VERSION "created by canmatrix"

NS_ :

BS_:

BU_: RadarFrontRight RadarFrontLeft DASy

BO_ 3221225472 VECTOR__INDEPENDENT_SIG_MSG: 0 Vector__XXX
 SG_ New_Signal_1313 : 0|8@1+ (1,0) [0|0] "" Vector__XXX
 SG_ ADAS_ModulationOffRequest : 0|2@1+ (1,0) [0|3] "" Vector__XXX

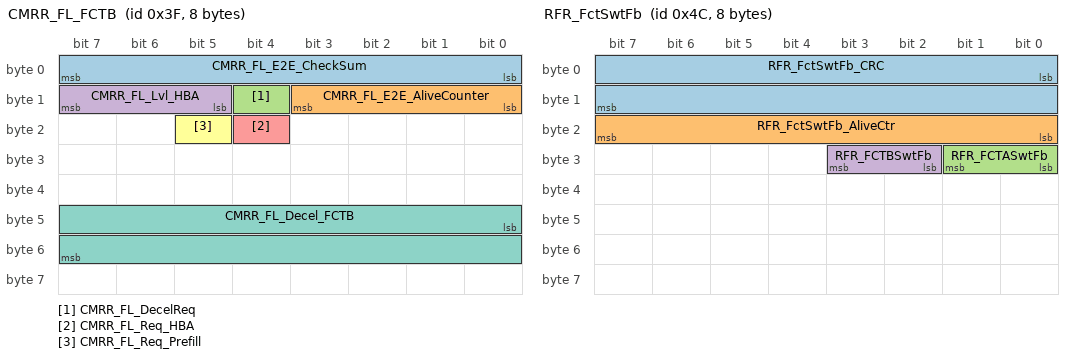
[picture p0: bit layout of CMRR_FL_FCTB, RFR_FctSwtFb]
BO_ 63 CMRR_FL_FCTB: 8 RadarFrontLeft
 SG_ CMRR_FL_E2E_CheckSum : 0|8@1+ (1,0) [0|255] ""  RadarFrontRight
 SG_ CMRR_FL_E2E_AliveCounter : 8|4@1+ (1,0) [0|14] ""  RadarFrontRight
 SG_ CMRR_FL_DecelReq : 12|1@1+ (1,0) [0|1] ""  RadarFrontRight
 SG_ CMRR_FL_Lvl_HBA : 13|3@1+ (1,0) [0|7] ""  RadarFrontRight
 SG_ CMRR_FL_Req_HBA : 20|1@1+ (1,0) [0|1] ""  RadarFrontRight
 SG_ CMRR_FL_Req_Prefill : 21|1@1+ (1,0) [0|1] ""  RadarFrontRight
 SG_ CMRR_FL_Decel_FCTB : 40|16@1+ (0.0004882,-16) [-16|15.994187] "m/s^2"  RadarFrontRight

BO_ 76 RFR_FctSwtFb: 8 RadarFrontRight
 SG_ RFR_FctSwtFb_CRC : 0|16@1+ (1,0) [0|65535] ""  DASy
 SG_ RFR_FctSwtFb_AliveCtr : 16|8@1+ (1,0) [0|255] ""  DASy
 SG_ RFR_FCTASwtFb : 24|2@1+ (1,0) [0|3] ""  DASy
 SG_ RFR_FCTBSwtFb : 26|2@1+ (1,0) [0|3] ""  DASy

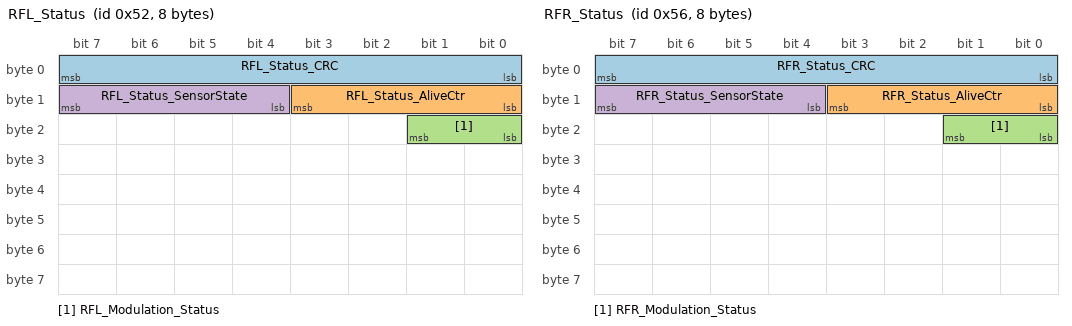
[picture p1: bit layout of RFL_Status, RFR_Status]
BO_ 82 RFL_Status: 8 RadarFrontLeft
 SG_ RFL_Status_CRC : 0|8@1+ (1,0) [0|255] ""  DASy
 SG_ RFL_Status_AliveCtr : 8|4@1+ (1,0) [0|14] ""  DASy
 SG_ RFL_Modulation_Status : 16|2@1+ (1,0) [0|3] ""  DASy
 SG_ RFL_Status_SensorState : 12|4@1+ (1,0) [0|15] ""  DASy

BO_ 86 RFR_Status: 8 RadarFrontRight
 SG_ RFR_Status_CRC : 0|8@1+ (1,0) [0|255] ""  DASy
 SG_ RFR_Status_AliveCtr : 8|4@1+ (1,0) [0|14] ""  DASy
 SG_ RFR_Modulation_Status : 16|2@1+ (1,0) [0|3] ""  DASy
 SG_ RFR_Status_SensorState : 12|4@1+ (1,0) [0|15] ""  DASy

BO_ 517 RFL_ObjHdr: 48 RadarFrontLeft
 SG_ RFL_ObjHdr_CRC : 0|16@1+ (1,0) [0|65535] ""  DASy
 SG_ RFL_ObjHdr_MountPosY : 128|8@1+ (0.01,-1.28) [-1.28|1.27] "m"  DASy
 SG_ RFL_ObjHdr_MountPosX : 136|9@1+ (0.02,-5.12) [-5.12|5.1] "m"  DASy
 SG_ RFL_ObjHdr_MountPosZ : 145|5@1+ (0.05,0) [0|1.55] "m"  DASy
 SG_ RFL_ObjHdr_ObjectDownSel : 151|1@1+ (1,0) [0|1] ""  DASy
 SG_ RFL_ObjHdr_YawMountAngle : 152|16@1+ (0.00017,-5.57056) [-3.2|3.2] "rad"  DASy
 SG_ RFL_ObjHdr_YawAngleLower : 168|15@1+ (0.00017,-2.78528) [-1.6|1.6] "rad"  DASy
 SG_ RFL_ObjHdr_AliveCtr : 16|8@1+ (1,0) [0|255] ""  DASy
 SG_ RFL_ObjHdr_AziOutOfSpec : 183|1@1+ (1,0) [0|1] ""  DASy
 SG_ RFL_ObjHdr_YawAngleUpper : 184|15@1+ (0.00017,-2.78528) [-1.6|1.6] "rad"  DASy
 SG_ RFL_ObjHdr_ElevOutOfSpec : 199|1@1+ (1,0) [0|1] ""  DASy
 SG_ RFL_ObjHdr_PitchMountAngle : 200|12@1+ (0.00017,-0.34816) [-0.2|0.2] "rad"  DASy
 SG_ RFL_ObjHdr_PitchAngleLower : 212|12@1+ (0.00017,-0.34816) [-0.2|0.2] "rad"  DASy
 SG_ RFL_ObjHdr_PitchAngleUpper : 224|12@1+ (0.00017,-0.34816) [-0.2|0.2] "rad"  DASy
 SG_ RFL_ObjHdr_RollMountAngle : 236|12@1+ (0.00017,-0.34816) [-0.2|0.2] "rad"  DASy
 SG_ RFL_ObjHdr_DetectionRange : 248|9@1+ (1,0) [0|511] "m"  DASy
 SG_ RFL_ObjHdr_ProtBlockCtr : 24|4@1+ (1,0) [0|15] ""  DASy
 SG_ RFL_ObjHdr_SensorState : 28|4@1+ (1,0) [0|15] ""  DASy
 SG_ RFL_ObjHdr_ProtocolVersion : 32|16@1+ (1,0) [0|65535] ""  DASy
 SG_ RFL_ObjHdr_ProtObjectCount : 48|6@1+ (1,0) [0|40] ""  DASy
 SG_ RFL_ObjHdr_TimeStampStatus : 88|8@1+ (1,0) [0|255] ""  DASy
 SG_ RFL_ObjHdr_TimeStamp : 96|26@1+ (1,0) [0|67108863] "ms"  DASy

BO_ 528 RFL_Obj00A: 64 RadarFrontLeft
 SG_ RFL_Obj00A_CRC : 0|16@1+ (1,0) [0|65535] ""  DASy
 SG_ RFL_Obj00A_Ay : 103|9@1+ (0.0625,-16) [-16|15.9375] "m/s^2"  DASy
 SG_ RFL_Obj00A_HeadingYawAngle : 112|9@1+ (0.0175,-4.48) [-3.15|3.15] "rad"  DASy
 SG_ RFL_Obj00A_Length : 121|7@1+ (0.125,0) [0|15.875] "m"  DASy
 SG_ RFL_Obj00A_Width : 128|7@1+ (0.125,0) [0|15.875] "m"  DASy
 SG_ RFL_Obj00A_Height : 135|7@1+ (0.125,0) [0|15.875] "m"  DASy
 SG_ RFL_Obj00A_DxVnce : 142|12@1+ (0.01,0) [0|30] "m^2"  DASy
 SG_ RFL_Obj00A_DyVnce : 154|12@1+ (0.01,0) [0|30] "m^2"  DASy
 SG_ RFL_Obj00A_DzVnce : 166|10@1+ (0.01,0) [0|10] "m^2"  DASy
 SG_ RFL_Obj00A_AliveCtr : 16|8@1+ (1,0) [0|255] ""  DASy
 SG_ RFL_Obj00A_VxVnce : 176|12@1+ (0.01,0) [0|30] "m^2/s^2"  DASy
 SG_ RFL_Obj00A_VyVnce : 188|12@1+ (0.01,0) [0|30] "m^2/s^2"  DASy
 SG_ RFL_Obj00A_AxVnce : 200|12@1+ (0.01,0) [0|30] "m^2/s^4"  DASy
 SG_ RFL_Obj00A_AyVnce : 212|12@1+ (0.01,0) [0|30] "m^2/s^4"  DASy
 SG_ RFL_Obj00A_RefPosIndex : 224|4@1+ (1,0) [0|15] ""  DASy
 SG_ RFL_Obj00A_DxDyCoVnce : 228|12@1+ (0.01,0) [0|30] "m^2"  DASy
 SG_ RFL_Obj00A_DxVxCoVnce : 240|12@1+ (0.01,0) [0|30] "m^2/s"  DASy
 SG_ RFL_Obj00A_ProtBlockCtr : 24|4@1+ (1,0) [0|15] ""  DASy
 SG_ RFL_Obj00A_DyVxCoVnce : 252|12@1+ (0.01,0) [0|30] "m^2/s"  DASy
 SG_ RFL_Obj00A_DxVyCoVnce : 264|12@1+ (0.01,0) [0|30] "m^2/s"  DASy
 SG_ RFL_Obj00A_DyVyCoVnce : 276|12@1+ (0.01,0) [0|30] "m^2/s"  DASy
 SG_ RFL_Obj00A_VxVyCoVnce : 288|12@1+ (0.01,0) [0|30] "m^2/s^2"  DASy
 SG_ RFL_Obj00A_DxAxCoVnce : 300|12@1+ (0.01,0) [0|30] "m^2/s^2"  DASy
 SG_ RFL_Obj00A_DyAxCoVnce : 312|12@1+ (0.01,0) [0|30] "m^2/s^2"  DASy
 SG_ RFL_Obj00A_VxAxCoVnce : 324|12@1+ (0.01,0) [0|30] "m^2/s^3"  DASy
 SG_ RFL_Obj00A_ID : 32|7@1+ (1,0) [0|127] ""  DASy
 SG_ RFL_Obj00A_VyAxCoVnce : 336|12@1+ (0.01,0) [0|30] "m^2/s^3"  DASy
 SG_ RFL_Obj00A_DxAyCoVnce : 348|12@1+ (0.01,0) [0|30] "m^2/s^2"  DASy
 SG_ RFL_Obj00A_DyAyCoVnce : 360|12@1+ (0.01,0) [0|30] "m^2/s^2"  DASy
 SG_ RFL_Obj00A_VxAyCoVnce : 372|12@1+ (0.01,0) [0|30] "m^2/s^3"  DASy
 SG_ RFL_Obj00A_VyAyCoVnce : 384|12@1+ (0.01,0) [0|30] "m^2/s^3"  DASy
 SG_ RFL_Obj00A_AxAyCoVnce : 396|12@1+ (0.01,0) [0|30] "m^2/s^4"  DASy
 SG_ RFL_Obj00A_Measured : 39|1@1+ (1,0) [0|1] ""  DASy
 SG_ RFL_Obj00A_HeadingYawAngleVnce : 408|12@1+ (0.0003,0) [0|1] "rad^2"  DASy
 SG_ RFL_Obj00A_Dx : 40|13@1+ (0.0625,-256) [-256|255.9375] "m"  DASy
 SG_ RFL_Obj00A_LengthVnce : 420|12@1+ (0.01,0) [0|30] "m^2"  DASy
 SG_ RFL_Obj00A_WidthVnce : 432|12@1+ (0.01,0) [0|30] "m^2"  DASy
 SG_ RFL_Obj00A_HeightVnce : 444|12@1+ (0.01,0) [0|30] "m^2"  DASy
 SG_ RFL_Obj00A_ProbExist : 456|6@1+ (2,0) [0|100] "%"  DASy
 SG_ RFL_Obj00A_ProbObstacle : 462|6@1+ (2,0) [0|100] "%"  DASy
 SG_ RFL_Obj00A_ProbNonObstacle : 468|6@1+ (2,0) [0|100] "%"  DASy
 SG_ RFL_Obj00A_ProbMobileObst : 474|6@1+ (2,0) [0|100] "%"  DASy
 SG_ RFL_Obj00A_Dz : 53|6@1+ (0.25,-5) [-5|10.75] "m"  DASy
 SG_ RFL_Obj00A_Dy : 59|11@1+ (0.125,-128) [-128|127.875] "m"  DASy
 SG_ RFL_Obj00A_Valid : 70|1@1+ (1,0) [0|1] ""  DASy
 SG_ RFL_Obj00A_Vx : 71|12@1+ (0.0625,-128) [-128|127.9375] "m/s"  DASy
 SG_ RFL_Obj00A_Vy : 83|10@1+ (0.125,-64) [-64|63.875] "m/s"  DASy
 SG_ RFL_Obj00A_Ax : 93|10@1+ (0.03125,-16) [-16|15.96875] "m/s^2"  DASy

BO_ 529 RFL_Obj00B: 12 RadarFrontLeft
 SG_ RFL_Obj00B_CRC : 0|16@1+ (1,0) [0|65535] ""  DASy
 SG_ RFL_Obj00B_AliveCtr : 16|8@1+ (1,0) [0|255] ""  DASy
 SG_ RFL_Obj00B_ProtBlockCtr : 24|4@1+ (1,0) [0|15] ""  DASy
 SG_ RFL_Obj00B_ProbMob4PlusWhl : 28|6@1+ (2,0) [0|100] "%"  DASy
 SG_ RFL_Obj00B_ProbMob2Whl : 34|6@1+ (2,0) [0|100] "%"  DASy
 SG_ RFL_Obj00B_ProbMobPed : 40|6@1+ (2,0) [0|100] "%"  DASy
 SG_ RFL_Obj00B_Prob4PlusWhlCAR : 46|6@1+ (2,0) [0|100] "%"  DASy
 SG_ RFL_Obj00B_Prob4PlusWhlbHGV : 52|6@1+ (2,0) [0|100] "%"  DASy
 SG_ RFL_Obj00B_ProbGNDReflex : 58|6@1+ (2,0) [0|100] "%"  DASy
 SG_ RFL_Obj00B_ProbStatBarrier : 64|6@1+ (2,0) [0|100] "%"  DASy
 SG_ RFL_Obj00B_ProbStatObst : 70|6@1+ (2,0) [0|100] "%"  DASy
 SG_ RFL_Obj00B_MovingProbability : 76|6@1+ (2,0) [0|100] "%"  DASy
 SG_ RFL_Obj00B_MovingObserved : 82|6@1+ (2,0) [0|100] "%"  DASy
 SG_ RFL_Obj00B_BehaviorType : 88|3@1+ (1,0) [0|7] ""  DASy

BO_ 530 RFL_Obj01A: 64 RadarFrontLeft
 SG_ RFL_Obj01A_CRC : 0|16@1+ (1,0) [0|65535] ""  DASy
 SG_ RFL_Obj01A_Ay : 103|9@1+ (0.0625,-16) [-16|15.9375] "m/s^2"  DASy
 SG_ RFL_Obj01A_HeadingYawAngle : 112|9@1+ (0.0175,-4.48) [-3.15|3.15] "rad"  DASy
 SG_ RFL_Obj01A_Length : 121|7@1+ (0.125,0) [0|15.875] "m"  DASy
 SG_ RFL_Obj01A_Width : 128|7@1+ (0.125,0) [0|15.875] "m"  DASy
 SG_ RFL_Obj01A_Height : 135|7@1+ (0.125,0) [0|15.875] "m"  DASy
 SG_ RFL_Obj01A_DxVnce : 142|12@1+ (0.01,0) [0|30] "m^2"  DASy
 SG_ RFL_Obj01A_DyVnce : 154|12@1+ (0.01,0) [0|30] "m^2"  DASy
 SG_ RFL_Obj01A_DzVnce : 166|10@1+ (0.01,0) [0|10] "m^2"  DASy
 SG_ RFL_Obj01A_AliveCtr : 16|8@1+ (1,0) [0|255] ""  DASy
 SG_ RFL_Obj01A_VxVnce : 176|12@1+ (0.01,0) [0|30] "m^2/s^2"  DASy
 SG_ RFL_Obj01A_VyVnce : 188|12@1+ (0.01,0) [0|30] "m^2/s^2"  DASy
 SG_ RFL_Obj01A_AxVnce : 200|12@1+ (0.01,0) [0|30] "m^2/s^4"  DASy
 SG_ RFL_Obj01A_AyVnce : 212|12@1+ (0.01,0) [0|30] "m^2/s^4"  DASy
 SG_ RFL_Obj01A_RefPosIndex : 224|4@1+ (1,0) [0|15] ""  DASy
 SG_ RFL_Obj01A_DxDyCoVnce : 228|12@1+ (0.01,0) [0|30] "m^2"  DASy
 SG_ RFL_Obj01A_DxVxCoVnce : 240|12@1+ (0.01,0) [0|30] "m^2/s"  DASy
 SG_ RFL_Obj01A_ProtBlockCtr : 24|4@1+ (1,0) [0|15] ""  DASy
 SG_ RFL_Obj01A_DyVxCoVnce : 252|12@1+ (0.01,0) [0|30] "m^2/s"  DASy
 SG_ RFL_Obj01A_DxVyCoVnce : 264|12@1+ (0.01,0) [0|30] "m^2/s"  DASy
 SG_ RFL_Obj01A_DyVyCoVnce : 276|12@1+ (0.01,0) [0|30] "m^2/s"  DASy
 SG_ RFL_Obj01A_VxVyCoVnce : 288|12@1+ (0.01,0) [0|30] "m^2/s^2"  DASy
 SG_ RFL_Obj01A_DxAxCoVnce : 300|12@1+ (0.01,0) [0|30] "m^2/s^2"  DASy
 SG_ RFL_Obj01A_DyAxCoVnce : 312|12@1+ (0.01,0) [0|30] "m^2/s^2"  DASy
 SG_ RFL_Obj01A_VxAxCoVnce : 324|12@1+ (0.01,0) [0|30] "m^2/s^3"  DASy
 SG_ RFL_Obj01A_ID : 32|7@1+ (1,0) [0|127] ""  DASy
 SG_ RFL_Obj01A_VyAxCoVnce : 336|12@1+ (0.01,0) [0|30] "m^2/s^3"  DASy
 SG_ RFL_Obj01A_DxAyCoVnce : 348|12@1+ (0.01,0) [0|30] "m^2/s^2"  DASy
 SG_ RFL_Obj01A_DyAyCoVnce : 360|12@1+ (0.01,0) [0|30] "m^2/s^2"  DASy
 SG_ RFL_Obj01A_VxAyCoVnce : 372|12@1+ (0.01,0) [0|30] "m^2/s^3"  DASy
 SG_ RFL_Obj01A_VyAyCoVnce : 384|12@1+ (0.01,0) [0|30] "m^2/s^3"  DASy
 SG_ RFL_Obj01A_AxAyCoVnce : 396|12@1+ (0.01,0) [0|30] "m^2/s^4"  DASy
 SG_ RFL_Obj01A_Measured : 39|1@1+ (1,0) [0|1] ""  DASy
 SG_ RFL_Obj01A_HeadingYawAngleVnce : 408|12@1+ (0.0003,0) [0|1] "rad^2"  DASy
 SG_ RFL_Obj01A_Dx : 40|13@1+ (0.0625,-256) [-256|255.9375] "m"  DASy
 SG_ RFL_Obj01A_LengthVnce : 420|12@1+ (0.01,0) [0|30] "m^2"  DASy
 SG_ RFL_Obj01A_WidthVnce : 432|12@1+ (0.01,0) [0|30] "m^2"  DASy
 SG_ RFL_Obj01A_HeightVnce : 444|12@1+ (0.01,0) [0|30] "m^2"  DASy
 SG_ RFL_Obj01A_ProbExist : 456|6@1+ (2,0) [0|100] "%"  DASy
 SG_ RFL_Obj01A_ProbObstacle : 462|6@1+ (2,0) [0|100] "%"  DASy
 SG_ RFL_Obj01A_ProbNonObstacle : 468|6@1+ (2,0) [0|100] "%"  DASy
 SG_ RFL_Obj01A_ProbMobileObst : 474|6@1+ (2,0) [0|100] "%"  DASy
 SG_ RFL_Obj01A_Dz : 53|6@1+ (0.25,-5) [-5|10.75] "m"  DASy
 SG_ RFL_Obj01A_Dy : 59|11@1+ (0.125,-128) [-128|127.875] "m"  DASy
 SG_ RFL_Obj01A_Valid : 70|1@1+ (1,0) [0|1] ""  DASy
 SG_ RFL_Obj01A_Vx : 71|12@1+ (0.0625,-128) [-128|127.9375] "m/s"  DASy
 SG_ RFL_Obj01A_Vy : 83|10@1+ (0.125,-64) [-64|63.875] "m/s"  DASy
 SG_ RFL_Obj01A_Ax : 93|10@1+ (0.03125,-16) [-16|15.96875] "m/s^2"  DASy

BO_ 531 RFL_Obj01B: 12 RadarFrontLeft
 SG_ RFL_Obj01B_CRC : 0|16@1+ (1,0) [0|65535] ""  DASy
 SG_ RFL_Obj01B_AliveCtr : 16|8@1+ (1,0) [0|255] ""  DASy
 SG_ RFL_Obj01B_ProtBlockCtr : 24|4@1+ (1,0) [0|15] ""  DASy
 SG_ RFL_Obj01B_ProbMob4PlusWhl : 28|6@1+ (2,0) [0|100] "%"  DASy
 SG_ RFL_Obj01B_ProbMob2Whl : 34|6@1+ (2,0) [0|100] "%"  DASy
 SG_ RFL_Obj01B_ProbMobPed : 40|6@1+ (2,0) [0|100] "%"  DASy
 SG_ RFL_Obj01B_Prob4PlusWhlCAR : 46|6@1+ (2,0) [0|100] "%"  DASy
 SG_ RFL_Obj01B_Prob4PlusWhlbHGV : 52|6@1+ (2,0) [0|100] "%"  DASy
 SG_ RFL_Obj01B_ProbGNDReflex : 58|6@1+ (2,0) [0|100] "%"  DASy
 SG_ RFL_Obj01B_ProbStatBarrier : 64|6@1+ (2,0) [0|100] "%"  DASy
 SG_ RFL_Obj01B_ProbStatObst : 70|6@1+ (2,0) [0|100] "%"  DASy
 SG_ RFL_Obj01B_MovingProbability : 76|6@1+ (2,0) [0|100] "%"  DASy
 SG_ RFL_Obj01B_MovingObserved : 82|6@1+ (2,0) [0|100] "%"  DASy
 SG_ RFL_Obj01B_BehaviorType : 88|3@1+ (1,0) [0|7] ""  DASy

BO_ 532 RFL_Obj02A: 64 RadarFrontLeft
 SG_ RFL_Obj02A_CRC : 0|16@1+ (1,0) [0|65535] ""  DASy
 SG_ RFL_Obj02A_Ay : 103|9@1+ (0.0625,-16) [-16|15.9375] "m/s^2"  DASy
 SG_ RFL_Obj02A_HeadingYawAngle : 112|9@1+ (0.0175,-4.48) [-3.15|3.15] "rad"  DASy
 SG_ RFL_Obj02A_Length : 121|7@1+ (0.125,0) [0|15.875] "m"  DASy
 SG_ RFL_Obj02A_Width : 128|7@1+ (0.125,0) [0|15.875] "m"  DASy
 SG_ RFL_Obj02A_Height : 135|7@1+ (0.125,0) [0|15.875] "m"  DASy
 SG_ RFL_Obj02A_DxVnce : 142|12@1+ (0.01,0) [0|30] "m^2"  DASy
 SG_ RFL_Obj02A_DyVnce : 154|12@1+ (0.01,0) [0|30] "m^2"  DASy
 SG_ RFL_Obj02A_DzVnce : 166|10@1+ (0.01,0) [0|10] "m^2"  DASy
 SG_ RFL_Obj02A_AliveCtr : 16|8@1+ (1,0) [0|255] ""  DASy
 SG_ RFL_Obj02A_VxVnce : 176|12@1+ (0.01,0) [0|30] "m^2/s^2"  DASy
 SG_ RFL_Obj02A_VyVnce : 188|12@1+ (0.01,0) [0|30] "m^2/s^2"  DASy
 SG_ RFL_Obj02A_AxVnce : 200|12@1+ (0.01,0) [0|30] "m^2/s^4"  DASy
 SG_ RFL_Obj02A_AyVnce : 212|12@1+ (0.01,0) [0|30] "m^2/s^4"  DASy
 SG_ RFL_Obj02A_RefPosIndex : 224|4@1+ (1,0) [0|15] ""  DASy
 SG_ RFL_Obj02A_DxDyCoVnce : 228|12@1+ (0.01,0) [0|30] "m^2"  DASy
 SG_ RFL_Obj02A_DxVxCoVnce : 240|12@1+ (0.01,0) [0|30] "m^2/s"  DASy
 SG_ RFL_Obj02A_ProtBlockCtr : 24|4@1+ (1,0) [0|15] ""  DASy
 SG_ RFL_Obj02A_DyVxCoVnce : 252|12@1+ (0.01,0) [0|30] "m^2/s"  DASy
 SG_ RFL_Obj02A_DxVyCoVnce : 264|12@1+ (0.01,0) [0|30] "m^2/s"  DASy
 SG_ RFL_Obj02A_DyVyCoVnce : 276|12@1+ (0.01,0) [0|30] "m^2/s"  DASy
 SG_ RFL_Obj02A_VxVyCoVnce : 288|12@1+ (0.01,0) [0|30] "m^2/s^2"  DASy
 SG_ RFL_Obj02A_DxAxCoVnce : 300|12@1+ (0.01,0) [0|30] "m^2/s^2"  DASy
 SG_ RFL_Obj02A_DyAxCoVnce : 312|12@1+ (0.01,0) [0|30] "m^2/s^2"  DASy
 SG_ RFL_Obj02A_VxAxCoVnce : 324|12@1+ (0.01,0) [0|30] "m^2/s^3"  DASy
 SG_ RFL_Obj02A_ID : 32|7@1+ (1,0) [0|127] ""  DASy
 SG_ RFL_Obj02A_VyAxCoVnce : 336|12@1+ (0.01,0) [0|30] "m^2/s^3"  DASy
 SG_ RFL_Obj02A_DxAyCoVnce : 348|12@1+ (0.01,0) [0|30] "m^2/s^2"  DASy
 SG_ RFL_Obj02A_DyAyCoVnce : 360|12@1+ (0.01,0) [0|30] "m^2/s^2"  DASy
 SG_ RFL_Obj02A_VxAyCoVnce : 372|12@1+ (0.01,0) [0|30] "m^2/s^3"  DASy
 SG_ RFL_Obj02A_VyAyCoVnce : 384|12@1+ (0.01,0) [0|30] "m^2/s^3"  DASy
 SG_ RFL_Obj02A_AxAyCoVnce : 396|12@1+ (0.01,0) [0|30] "m^2/s^4"  DASy
 SG_ RFL_Obj02A_Measured : 39|1@1+ (1,0) [0|1] ""  DASy
 SG_ RFL_Obj02A_HeadingYawAngleVnce : 408|12@1+ (0.0003,0) [0|1] "rad^2"  DASy
 SG_ RFL_Obj02A_Dx : 40|13@1+ (0.0625,-256) [-256|255.9375] "m"  DASy
 SG_ RFL_Obj02A_LengthVnce : 420|12@1+ (0.01,0) [0|30] "m^2"  DASy
 SG_ RFL_Obj02A_WidthVnce : 432|12@1+ (0.01,0) [0|30] "m^2"  DASy
 SG_ RFL_Obj02A_HeightVnce : 444|12@1+ (0.01,0) [0|30] "m^2"  DASy
 SG_ RFL_Obj02A_ProbExist : 456|6@1+ (2,0) [0|100] "%"  DASy
 SG_ RFL_Obj02A_ProbObstacle : 462|6@1+ (2,0) [0|100] "%"  DASy
 SG_ RFL_Obj02A_ProbNonObstacle : 468|6@1+ (2,0) [0|100] "%"  DASy
 SG_ RFL_Obj02A_ProbMobileObst : 474|6@1+ (2,0) [0|100] "%"  DASy
 SG_ RFL_Obj02A_Dz : 53|6@1+ (0.25,-5) [-5|10.75] "m"  DASy
 SG_ RFL_Obj02A_Dy : 59|11@1+ (0.125,-128) [-128|127.875] "m"  DASy
 SG_ RFL_Obj02A_Valid : 70|1@1+ (1,0) [0|1] ""  DASy
 SG_ RFL_Obj02A_Vx : 71|12@1+ (0.0625,-128) [-128|127.9375] "m/s"  DASy
 SG_ RFL_Obj02A_Vy : 83|10@1+ (0.125,-64) [-64|63.875] "m/s"  DASy
 SG_ RFL_Obj02A_Ax : 93|10@1+ (0.03125,-16) [-16|15.96875] "m/s^2"  DASy

BO_ 533 RFL_Obj02B: 12 RadarFrontLeft
 SG_ RFL_Obj02B_CRC : 0|16@1+ (1,0) [0|65535] ""  DASy
 SG_ RFL_Obj02B_AliveCtr : 16|8@1+ (1,0) [0|255] ""  DASy
 SG_ RFL_Obj02B_ProtBlockCtr : 24|4@1+ (1,0) [0|15] ""  DASy
 SG_ RFL_Obj02B_ProbMob4PlusWhl : 28|6@1+ (2,0) [0|100] "%"  DASy
 SG_ RFL_Obj02B_ProbMob2Whl : 34|6@1+ (2,0) [0|100] "%"  DASy
 SG_ RFL_Obj02B_ProbMobPed : 40|6@1+ (2,0) [0|100] "%"  DASy
 SG_ RFL_Obj02B_Prob4PlusWhlCAR : 46|6@1+ (2,0) [0|100] "%"  DASy
 SG_ RFL_Obj02B_Prob4PlusWhlbHGV : 52|6@1+ (2,0) [0|100] "%"  DASy
 SG_ RFL_Obj02B_ProbGNDReflex : 58|6@1+ (2,0) [0|100] "%"  DASy
 SG_ RFL_Obj02B_ProbStatBarrier : 64|6@1+ (2,0) [0|100] "%"  DASy
 SG_ RFL_Obj02B_ProbStatObst : 70|6@1+ (2,0) [0|100] "%"  DASy
 SG_ RFL_Obj02B_MovingProbability : 76|6@1+ (2,0) [0|100] "%"  DASy
 SG_ RFL_Obj02B_MovingObserved : 82|6@1+ (2,0) [0|100] "%"  DASy
 SG_ RFL_Obj02B_BehaviorType : 88|3@1+ (1,0) [0|7] ""  DASy

BO_ 534 RFL_Obj03A: 64 RadarFrontLeft
 SG_ RFL_Obj03A_CRC : 0|16@1+ (1,0) [0|65535] ""  DASy
 SG_ RFL_Obj03A_Ay : 103|9@1+ (0.0625,-16) [-16|15.9375] "m/s^2"  DASy
 SG_ RFL_Obj03A_HeadingYawAngle : 112|9@1+ (0.0175,-4.48) [-3.15|3.15] "rad"  DASy
 SG_ RFL_Obj03A_Length : 121|7@1+ (0.125,0) [0|15.875] "m"  DASy
 SG_ RFL_Obj03A_Width : 128|7@1+ (0.125,0) [0|15.875] "m"  DASy
 SG_ RFL_Obj03A_Height : 135|7@1+ (0.125,0) [0|15.875] "m"  DASy
 SG_ RFL_Obj03A_DxVnce : 142|12@1+ (0.01,0) [0|30] "m^2"  DASy
 SG_ RFL_Obj03A_DyVnce : 154|12@1+ (0.01,0) [0|30] "m^2"  DASy
 SG_ RFL_Obj03A_DzVnce : 166|10@1+ (0.01,0) [0|10] "m^2"  DASy
 SG_ RFL_Obj03A_AliveCtr : 16|8@1+ (1,0) [0|255] ""  DASy
 SG_ RFL_Obj03A_VxVnce : 176|12@1+ (0.01,0) [0|30] "m^2/s^2"  DASy
 SG_ RFL_Obj03A_VyVnce : 188|12@1+ (0.01,0) [0|30] "m^2/s^2"  DASy
 SG_ RFL_Obj03A_AxVnce : 200|12@1+ (0.01,0) [0|30] "m^2/s^4"  DASy
 SG_ RFL_Obj03A_AyVnce : 212|12@1+ (0.01,0) [0|30] "m^2/s^4"  DASy
 SG_ RFL_Obj03A_RefPosIndex : 224|4@1+ (1,0) [0|15] ""  DASy
 SG_ RFL_Obj03A_DxDyCoVnce : 228|12@1+ (0.01,0) [0|30] "m^2"  DASy
 SG_ RFL_Obj03A_DxVxCoVnce : 240|12@1+ (0.01,0) [0|30] "m^2/s"  DASy
 SG_ RFL_Obj03A_ProtBlockCtr : 24|4@1+ (1,0) [0|15] ""  DASy
 SG_ RFL_Obj03A_DyVxCoVnce : 252|12@1+ (0.01,0) [0|30] "m^2/s"  DASy
 SG_ RFL_Obj03A_DxVyCoVnce : 264|12@1+ (0.01,0) [0|30] "m^2/s"  DASy
 SG_ RFL_Obj03A_DyVyCoVnce : 276|12@1+ (0.01,0) [0|30] "m^2/s"  DASy
 SG_ RFL_Obj03A_VxVyCoVnce : 288|12@1+ (0.01,0) [0|30] "m^2/s^2"  DASy
 SG_ RFL_Obj03A_DxAxCoVnce : 300|12@1+ (0.01,0) [0|30] "m^2/s^2"  DASy
 SG_ RFL_Obj03A_DyAxCoVnce : 312|12@1+ (0.01,0) [0|30] "m^2/s^2"  DASy
 SG_ RFL_Obj03A_VxAxCoVnce : 324|12@1+ (0.01,0) [0|30] "m^2/s^3"  DASy
 SG_ RFL_Obj03A_ID : 32|7@1+ (1,0) [0|127] ""  DASy
 SG_ RFL_Obj03A_VyAxCoVnce : 336|12@1+ (0.01,0) [0|30] "m^2/s^3"  DASy
 SG_ RFL_Obj03A_DxAyCoVnce : 348|12@1+ (0.01,0) [0|30] "m^2/s^2"  DASy
 SG_ RFL_Obj03A_DyAyCoVnce : 360|12@1+ (0.01,0) [0|30] "m^2/s^2"  DASy
 SG_ RFL_Obj03A_VxAyCoVnce : 372|12@1+ (0.01,0) [0|30] "m^2/s^3"  DASy
 SG_ RFL_Obj03A_VyAyCoVnce : 384|12@1+ (0.01,0) [0|30] "m^2/s^3"  DASy
 SG_ RFL_Obj03A_AxAyCoVnce : 396|12@1+ (0.01,0) [0|30] "m^2/s^4"  DASy
 SG_ RFL_Obj03A_Measured : 39|1@1+ (1,0) [0|1] ""  DASy
 SG_ RFL_Obj03A_HeadingYawAngleVnce : 408|12@1+ (0.0003,0) [0|1] "rad^2"  DASy
 SG_ RFL_Obj03A_Dx : 40|13@1+ (0.0625,-256) [-256|255.9375] "m"  DASy
 SG_ RFL_Obj03A_LengthVnce : 420|12@1+ (0.01,0) [0|30] "m^2"  DASy
 SG_ RFL_Obj03A_WidthVnce : 432|12@1+ (0.01,0) [0|30] "m^2"  DASy
 SG_ RFL_Obj03A_HeightVnce : 444|12@1+ (0.01,0) [0|30] "m^2"  DASy
 SG_ RFL_Obj03A_ProbExist : 456|6@1+ (2,0) [0|100] "%"  DASy
 SG_ RFL_Obj03A_ProbObstacle : 462|6@1+ (2,0) [0|100] "%"  DASy
 SG_ RFL_Obj03A_ProbNonObstacle : 468|6@1+ (2,0) [0|100] "%"  DASy
 SG_ RFL_Obj03A_ProbMobileObst : 474|6@1+ (2,0) [0|100] "%"  DASy
 SG_ RFL_Obj03A_Dz : 53|6@1+ (0.25,-5) [-5|10.75] "m"  DASy
 SG_ RFL_Obj03A_Dy : 59|11@1+ (0.125,-128) [-128|127.875] "m"  DASy
 SG_ RFL_Obj03A_Valid : 70|1@1+ (1,0) [0|1] ""  DASy
 SG_ RFL_Obj03A_Vx : 71|12@1+ (0.0625,-128) [-128|127.9375] "m/s"  DASy
 SG_ RFL_Obj03A_Vy : 83|10@1+ (0.125,-64) [-64|63.875] "m/s"  DASy
 SG_ RFL_Obj03A_Ax : 93|10@1+ (0.03125,-16) [-16|15.96875] "m/s^2"  DASy

BO_ 535 RFL_Obj03B: 12 RadarFrontLeft
 SG_ RFL_Obj03B_CRC : 0|16@1+ (1,0) [0|65535] ""  DASy
 SG_ RFL_Obj03B_AliveCtr : 16|8@1+ (1,0) [0|255] ""  DASy
 SG_ RFL_Obj03B_ProtBlockCtr : 24|4@1+ (1,0) [0|15] ""  DASy
 SG_ RFL_Obj03B_ProbMob4PlusWhl : 28|6@1+ (2,0) [0|100] "%"  DASy
 SG_ RFL_Obj03B_ProbMob2Whl : 34|6@1+ (2,0) [0|100] "%"  DASy
 SG_ RFL_Obj03B_ProbMobPed : 40|6@1+ (2,0) [0|100] "%"  DASy
 SG_ RFL_Obj03B_Prob4PlusWhlCAR : 46|6@1+ (2,0) [0|100] "%"  DASy
 SG_ RFL_Obj03B_Prob4PlusWhlbHGV : 52|6@1+ (2,0) [0|100] "%"  DASy
 SG_ RFL_Obj03B_ProbGNDReflex : 58|6@1+ (2,0) [0|100] "%"  DASy
 SG_ RFL_Obj03B_ProbStatBarrier : 64|6@1+ (2,0) [0|100] "%"  DASy
 SG_ RFL_Obj03B_ProbStatObst : 70|6@1+ (2,0) [0|100] "%"  DASy
 SG_ RFL_Obj03B_MovingProbability : 76|6@1+ (2,0) [0|100] "%"  DASy
 SG_ RFL_Obj03B_MovingObserved : 82|6@1+ (2,0) [0|100] "%"  DASy
 SG_ RFL_Obj03B_BehaviorType : 88|3@1+ (1,0) [0|7] ""  DASy

BO_ 536 RFL_Obj04A: 64 RadarFrontLeft
 SG_ RFL_Obj04A_CRC : 0|16@1+ (1,0) [0|65535] ""  DASy
 SG_ RFL_Obj04A_Ay : 103|9@1+ (0.0625,-16) [-16|15.9375] "m/s^2"  DASy
 SG_ RFL_Obj04A_HeadingYawAngle : 112|9@1+ (0.0175,-4.48) [-3.15|3.15] "rad"  DASy
 SG_ RFL_Obj04A_Length : 121|7@1+ (0.125,0) [0|15.875] "m"  DASy
 SG_ RFL_Obj04A_Width : 128|7@1+ (0.125,0) [0|15.875] "m"  DASy
 SG_ RFL_Obj04A_Height : 135|7@1+ (0.125,0) [0|15.875] "m"  DASy
 SG_ RFL_Obj04A_DxVnce : 142|12@1+ (0.01,0) [0|30] "m^2"  DASy
 SG_ RFL_Obj04A_DyVnce : 154|12@1+ (0.01,0) [0|30] "m^2"  DASy
 SG_ RFL_Obj04A_DzVnce : 166|10@1+ (0.01,0) [0|10] "m^2"  DASy
 SG_ RFL_Obj04A_AliveCtr : 16|8@1+ (1,0) [0|255] ""  DASy
 SG_ RFL_Obj04A_VxVnce : 176|12@1+ (0.01,0) [0|30] "m^2/s^2"  DASy
 SG_ RFL_Obj04A_VyVnce : 188|12@1+ (0.01,0) [0|30] "m^2/s^2"  DASy
 SG_ RFL_Obj04A_AxVnce : 200|12@1+ (0.01,0) [0|30] "m^2/s^4"  DASy
 SG_ RFL_Obj04A_AyVnce : 212|12@1+ (0.01,0) [0|30] "m^2/s^4"  DASy
 SG_ RFL_Obj04A_RefPosIndex : 224|4@1+ (1,0) [0|15] ""  DASy
 SG_ RFL_Obj04A_DxDyCoVnce : 228|12@1+ (0.01,0) [0|30] "m^2"  DASy
 SG_ RFL_Obj04A_DxVxCoVnce : 240|12@1+ (0.01,0) [0|30] "m^2/s"  DASy
 SG_ RFL_Obj04A_ProtBlockCtr : 24|4@1+ (1,0) [0|15] ""  DASy
 SG_ RFL_Obj04A_DyVxCoVnce : 252|12@1+ (0.01,0) [0|30] "m^2/s"  DASy
 SG_ RFL_Obj04A_DxVyCoVnce : 264|12@1+ (0.01,0) [0|30] "m^2/s"  DASy
 SG_ RFL_Obj04A_DyVyCoVnce : 276|12@1+ (0.01,0) [0|30] "m^2/s"  DASy
 SG_ RFL_Obj04A_VxVyCoVnce : 288|12@1+ (0.01,0) [0|30] "m^2/s^2"  DASy
 SG_ RFL_Obj04A_DxAxCoVnce : 300|12@1+ (0.01,0) [0|30] "m^2/s^2"  DASy
 SG_ RFL_Obj04A_DyAxCoVnce : 312|12@1+ (0.01,0) [0|30] "m^2/s^2"  DASy
 SG_ RFL_Obj04A_VxAxCoVnce : 324|12@1+ (0.01,0) [0|30] "m^2/s^3"  DASy
 SG_ RFL_Obj04A_ID : 32|7@1+ (1,0) [0|127] ""  DASy
 SG_ RFL_Obj04A_VyAxCoVnce : 336|12@1+ (0.01,0) [0|30] "m^2/s^3"  DASy
 SG_ RFL_Obj04A_DxAyCoVnce : 348|12@1+ (0.01,0) [0|30] "m^2/s^2"  DASy
 SG_ RFL_Obj04A_DyAyCoVnce : 360|12@1+ (0.01,0) [0|30] "m^2/s^2"  DASy
 SG_ RFL_Obj04A_VxAyCoVnce : 372|12@1+ (0.01,0) [0|30] "m^2/s^3"  DASy
 SG_ RFL_Obj04A_VyAyCoVnce : 384|12@1+ (0.01,0) [0|30] "m^2/s^3"  DASy
 SG_ RFL_Obj04A_AxAyCoVnce : 396|12@1+ (0.01,0) [0|30] "m^2/s^4"  DASy
 SG_ RFL_Obj04A_Measured : 39|1@1+ (1,0) [0|1] ""  DASy
 SG_ RFL_Obj04A_HeadingYawAngleVnce : 408|12@1+ (0.0003,0) [0|1] "rad^2"  DASy
 SG_ RFL_Obj04A_Dx : 40|13@1+ (0.0625,-256) [-256|255.9375] "m"  DASy
 SG_ RFL_Obj04A_LengthVnce : 420|12@1+ (0.01,0) [0|30] "m^2"  DASy
 SG_ RFL_Obj04A_WidthVnce : 432|12@1+ (0.01,0) [0|30] "m^2"  DASy
 SG_ RFL_Obj04A_HeightVnce : 444|12@1+ (0.01,0) [0|30] "m^2"  DASy
 SG_ RFL_Obj04A_ProbExist : 456|6@1+ (2,0) [0|100] "%"  DASy
 SG_ RFL_Obj04A_ProbObstacle : 462|6@1+ (2,0) [0|100] "%"  DASy
 SG_ RFL_Obj04A_ProbNonObstacle : 468|6@1+ (2,0) [0|100] "%"  DASy
 SG_ RFL_Obj04A_ProbMobileObst : 474|6@1+ (2,0) [0|100] "%"  DASy
 SG_ RFL_Obj04A_Dz : 53|6@1+ (0.25,-5) [-5|10.75] "m"  DASy
 SG_ RFL_Obj04A_Dy : 59|11@1+ (0.125,-128) [-128|127.875] "m"  DASy
 SG_ RFL_Obj04A_Valid : 70|1@1+ (1,0) [0|1] ""  DASy
 SG_ RFL_Obj04A_Vx : 71|12@1+ (0.0625,-128) [-128|127.9375] "m/s"  DASy
 SG_ RFL_Obj04A_Vy : 83|10@1+ (0.125,-64) [-64|63.875] "m/s"  DASy
 SG_ RFL_Obj04A_Ax : 93|10@1+ (0.03125,-16) [-16|15.96875] "m/s^2"  DASy

BO_ 537 RFL_Obj04B: 12 RadarFrontLeft
 SG_ RFL_Obj04B_CRC : 0|16@1+ (1,0) [0|65535] ""  DASy
 SG_ RFL_Obj04B_AliveCtr : 16|8@1+ (1,0) [0|255] ""  DASy
 SG_ RFL_Obj04B_ProtBlockCtr : 24|4@1+ (1,0) [0|15] ""  DASy
 SG_ RFL_Obj04B_ProbMob4PlusWhl : 28|6@1+ (2,0) [0|100] "%"  DASy
 SG_ RFL_Obj04B_ProbMob2Whl : 34|6@1+ (2,0) [0|100] "%"  DASy
 SG_ RFL_Obj04B_ProbMobPed : 40|6@1+ (2,0) [0|100] "%"  DASy
 SG_ RFL_Obj04B_Prob4PlusWhlCAR : 46|6@1+ (2,0) [0|100] "%"  DASy
 SG_ RFL_Obj04B_Prob4PlusWhlbHGV : 52|6@1+ (2,0) [0|100] "%"  DASy
 SG_ RFL_Obj04B_ProbGNDReflex : 58|6@1+ (2,0) [0|100] "%"  DASy
 SG_ RFL_Obj04B_ProbStatBarrier : 64|6@1+ (2,0) [0|100] "%"  DASy
 SG_ RFL_Obj04B_ProbStatObst : 70|6@1+ (2,0) [0|100] "%"  DASy
 SG_ RFL_Obj04B_MovingProbability : 76|6@1+ (2,0) [0|100] "%"  DASy
 SG_ RFL_Obj04B_MovingObserved : 82|6@1+ (2,0) [0|100] "%"  DASy
 SG_ RFL_Obj04B_BehaviorType : 88|3@1+ (1,0) [0|7] ""  DASy

BO_ 538 RFL_Obj05A: 64 RadarFrontLeft
 SG_ RFL_Obj05A_CRC : 0|16@1+ (1,0) [0|65535] ""  DASy
 SG_ RFL_Obj05A_Ay : 103|9@1+ (0.0625,-16) [-16|15.9375] "m/s^2"  DASy
 SG_ RFL_Obj05A_HeadingYawAngle : 112|9@1+ (0.0175,-4.48) [-3.15|3.15] "rad"  DASy
 SG_ RFL_Obj05A_Length : 121|7@1+ (0.125,0) [0|15.875] "m"  DASy
 SG_ RFL_Obj05A_Width : 128|7@1+ (0.125,0) [0|15.875] "m"  DASy
 SG_ RFL_Obj05A_Height : 135|7@1+ (0.125,0) [0|15.875] "m"  DASy
 SG_ RFL_Obj05A_DxVnce : 142|12@1+ (0.01,0) [0|30] "m^2"  DASy
 SG_ RFL_Obj05A_DyVnce : 154|12@1+ (0.01,0) [0|30] "m^2"  DASy
 SG_ RFL_Obj05A_DzVnce : 166|10@1+ (0.01,0) [0|10] "m^2"  DASy
 SG_ RFL_Obj05A_AliveCtr : 16|8@1+ (1,0) [0|255] ""  DASy
 SG_ RFL_Obj05A_VxVnce : 176|12@1+ (0.01,0) [0|30] "m^2/s^2"  DASy
 SG_ RFL_Obj05A_VyVnce : 188|12@1+ (0.01,0) [0|30] "m^2/s^2"  DASy
 SG_ RFL_Obj05A_AxVnce : 200|12@1+ (0.01,0) [0|30] "m^2/s^4"  DASy
 SG_ RFL_Obj05A_AyVnce : 212|12@1+ (0.01,0) [0|30] "m^2/s^4"  DASy
 SG_ RFL_Obj05A_RefPosIndex : 224|4@1+ (1,0) [0|15] ""  DASy
 SG_ RFL_Obj05A_DxDyCoVnce : 228|12@1+ (0.01,0) [0|30] "m^2"  DASy
 SG_ RFL_Obj05A_DxVxCoVnce : 240|12@1+ (0.01,0) [0|30] "m^2/s"  DASy
 SG_ RFL_Obj05A_ProtBlockCtr : 24|4@1+ (1,0) [0|15] ""  DASy
 SG_ RFL_Obj05A_DyVxCoVnce : 252|12@1+ (0.01,0) [0|30] "m^2/s"  DASy
 SG_ RFL_Obj05A_DxVyCoVnce : 264|12@1+ (0.01,0) [0|30] "m^2/s"  DASy
 SG_ RFL_Obj05A_DyVyCoVnce : 276|12@1+ (0.01,0) [0|30] "m^2/s"  DASy
 SG_ RFL_Obj05A_VxVyCoVnce : 288|12@1+ (0.01,0) [0|30] "m^2/s^2"  DASy
 SG_ RFL_Obj05A_DxAxCoVnce : 300|12@1+ (0.01,0) [0|30] "m^2/s^2"  DASy
 SG_ RFL_Obj05A_DyAxCoVnce : 312|12@1+ (0.01,0) [0|30] "m^2/s^2"  DASy
 SG_ RFL_Obj05A_VxAxCoVnce : 324|12@1+ (0.01,0) [0|30] "m^2/s^3"  DASy
 SG_ RFL_Obj05A_ID : 32|7@1+ (1,0) [0|127] ""  DASy
 SG_ RFL_Obj05A_VyAxCoVnce : 336|12@1+ (0.01,0) [0|30] "m^2/s^3"  DASy
 SG_ RFL_Obj05A_DxAyCoVnce : 348|12@1+ (0.01,0) [0|30] "m^2/s^2"  DASy
 SG_ RFL_Obj05A_DyAyCoVnce : 360|12@1+ (0.01,0) [0|30] "m^2/s^2"  DASy
 SG_ RFL_Obj05A_VxAyCoVnce : 372|12@1+ (0.01,0) [0|30] "m^2/s^3"  DASy
 SG_ RFL_Obj05A_VyAyCoVnce : 384|12@1+ (0.01,0) [0|30] "m^2/s^3"  DASy
 SG_ RFL_Obj05A_AxAyCoVnce : 396|12@1+ (0.01,0) [0|30] "m^2/s^4"  DASy
 SG_ RFL_Obj05A_Measured : 39|1@1+ (1,0) [0|1] ""  DASy
 SG_ RFL_Obj05A_HeadingYawAngleVnce : 408|12@1+ (0.0003,0) [0|1] "rad^2"  DASy
 SG_ RFL_Obj05A_Dx : 40|13@1+ (0.0625,-256) [-256|255.9375] "m"  DASy
 SG_ RFL_Obj05A_LengthVnce : 420|12@1+ (0.01,0) [0|30] "m^2"  DASy
 SG_ RFL_Obj05A_WidthVnce : 432|12@1+ (0.01,0) [0|30] "m^2"  DASy
 SG_ RFL_Obj05A_HeightVnce : 444|12@1+ (0.01,0) [0|30] "m^2"  DASy
 SG_ RFL_Obj05A_ProbExist : 456|6@1+ (2,0) [0|100] "%"  DASy
 SG_ RFL_Obj05A_ProbObstacle : 462|6@1+ (2,0) [0|100] "%"  DASy
 SG_ RFL_Obj05A_ProbNonObstacle : 468|6@1+ (2,0) [0|100] "%"  DASy
 SG_ RFL_Obj05A_ProbMobileObst : 474|6@1+ (2,0) [0|100] "%"  DASy
 SG_ RFL_Obj05A_Dz : 53|6@1+ (0.25,-5) [-5|10.75] "m"  DASy
 SG_ RFL_Obj05A_Dy : 59|11@1+ (0.125,-128) [-128|127.875] "m"  DASy
 SG_ RFL_Obj05A_Valid : 70|1@1+ (1,0) [0|1] ""  DASy
 SG_ RFL_Obj05A_Vx : 71|12@1+ (0.0625,-128) [-128|127.9375] "m/s"  DASy
 SG_ RFL_Obj05A_Vy : 83|10@1+ (0.125,-64) [-64|63.875] "m/s"  DASy
 SG_ RFL_Obj05A_Ax : 93|10@1+ (0.03125,-16) [-16|15.96875] "m/s^2"  DASy

BO_ 539 RFL_Obj05B: 12 RadarFrontLeft
 SG_ RFL_Obj05B_CRC : 0|16@1+ (1,0) [0|65535] ""  DASy
 SG_ RFL_Obj05B_AliveCtr : 16|8@1+ (1,0) [0|255] ""  DASy
 SG_ RFL_Obj05B_ProtBlockCtr : 24|4@1+ (1,0) [0|15] ""  DASy
 SG_ RFL_Obj05B_ProbMob4PlusWhl : 28|6@1+ (2,0) [0|100] "%"  DASy
 SG_ RFL_Obj05B_ProbMob2Whl : 34|6@1+ (2,0) [0|100] "%"  DASy
 SG_ RFL_Obj05B_ProbMobPed : 40|6@1+ (2,0) [0|100] "%"  DASy
 SG_ RFL_Obj05B_Prob4PlusWhlCAR : 46|6@1+ (2,0) [0|100] "%"  DASy
 SG_ RFL_Obj05B_Prob4PlusWhlbHGV : 52|6@1+ (2,0) [0|100] "%"  DASy
 SG_ RFL_Obj05B_ProbGNDReflex : 58|6@1+ (2,0) [0|100] "%"  DASy
 SG_ RFL_Obj05B_ProbStatBarrier : 64|6@1+ (2,0) [0|100] "%"  DASy
 SG_ RFL_Obj05B_ProbStatObst : 70|6@1+ (2,0) [0|100] "%"  DASy
 SG_ RFL_Obj05B_MovingProbability : 76|6@1+ (2,0) [0|100] "%"  DASy
 SG_ RFL_Obj05B_MovingObserved : 82|6@1+ (2,0) [0|100] "%"  DASy
 SG_ RFL_Obj05B_BehaviorType : 88|3@1+ (1,0) [0|7] ""  DASy

BO_ 540 RFL_Obj06A: 64 RadarFrontLeft
 SG_ RFL_Obj06A_CRC : 0|16@1+ (1,0) [0|65535] ""  DASy
 SG_ RFL_Obj06A_Ay : 103|9@1+ (0.0625,-16) [-16|15.9375] "m/s^2"  DASy
 SG_ RFL_Obj06A_HeadingYawAngle : 112|9@1+ (0.0175,-4.48) [-3.15|3.15] "rad"  DASy
 SG_ RFL_Obj06A_Length : 121|7@1+ (0.125,0) [0|15.875] "m"  DASy
 SG_ RFL_Obj06A_Width : 128|7@1+ (0.125,0) [0|15.875] "m"  DASy
 SG_ RFL_Obj06A_Height : 135|7@1+ (0.125,0) [0|15.875] "m"  DASy
 SG_ RFL_Obj06A_DxVnce : 142|12@1+ (0.01,0) [0|30] "m^2"  DASy
 SG_ RFL_Obj06A_DyVnce : 154|12@1+ (0.01,0) [0|30] "m^2"  DASy
 SG_ RFL_Obj06A_DzVnce : 166|10@1+ (0.01,0) [0|10] "m^2"  DASy
 SG_ RFL_Obj06A_AliveCtr : 16|8@1+ (1,0) [0|255] ""  DASy
 SG_ RFL_Obj06A_VxVnce : 176|12@1+ (0.01,0) [0|30] "m^2/s^2"  DASy
 SG_ RFL_Obj06A_VyVnce : 188|12@1+ (0.01,0) [0|30] "m^2/s^2"  DASy
 SG_ RFL_Obj06A_AxVnce : 200|12@1+ (0.01,0) [0|30] "m^2/s^4"  DASy
 SG_ RFL_Obj06A_AyVnce : 212|12@1+ (0.01,0) [0|30] "m^2/s^4"  DASy
 SG_ RFL_Obj06A_RefPosIndex : 224|4@1+ (1,0) [0|15] ""  DASy
 SG_ RFL_Obj06A_DxDyCoVnce : 228|12@1+ (0.01,0) [0|30] "m^2"  DASy
 SG_ RFL_Obj06A_DxVxCoVnce : 240|12@1+ (0.01,0) [0|30] "m^2/s"  DASy
 SG_ RFL_Obj06A_ProtBlockCtr : 24|4@1+ (1,0) [0|15] ""  DASy
 SG_ RFL_Obj06A_DyVxCoVnce : 252|12@1+ (0.01,0) [0|30] "m^2/s"  DASy
 SG_ RFL_Obj06A_DxVyCoVnce : 264|12@1+ (0.01,0) [0|30] "m^2/s"  DASy
 SG_ RFL_Obj06A_DyVyCoVnce : 276|12@1+ (0.01,0) [0|30] "m^2/s"  DASy
 SG_ RFL_Obj06A_VxVyCoVnce : 288|12@1+ (0.01,0) [0|30] "m^2/s^2"  DASy
 SG_ RFL_Obj06A_DxAxCoVnce : 300|12@1+ (0.01,0) [0|30] "m^2/s^2"  DASy
 SG_ RFL_Obj06A_DyAxCoVnce : 312|12@1+ (0.01,0) [0|30] "m^2/s^2"  DASy
 SG_ RFL_Obj06A_VxAxCoVnce : 324|12@1+ (0.01,0) [0|30] "m^2/s^3"  DASy
 SG_ RFL_Obj06A_ID : 32|7@1+ (1,0) [0|127] ""  DASy
 SG_ RFL_Obj06A_VyAxCoVnce : 336|12@1+ (0.01,0) [0|30] "m^2/s^3"  DASy
 SG_ RFL_Obj06A_DxAyCoVnce : 348|12@1+ (0.01,0) [0|30] "m^2/s^2"  DASy
 SG_ RFL_Obj06A_DyAyCoVnce : 360|12@1+ (0.01,0) [0|30] "m^2/s^2"  DASy
 SG_ RFL_Obj06A_VxAyCoVnce : 372|12@1+ (0.01,0) [0|30] "m^2/s^3"  DASy
 SG_ RFL_Obj06A_VyAyCoVnce : 384|12@1+ (0.01,0) [0|30] "m^2/s^3"  DASy
 SG_ RFL_Obj06A_AxAyCoVnce : 396|12@1+ (0.01,0) [0|30] "m^2/s^4"  DASy
 SG_ RFL_Obj06A_Measured : 39|1@1+ (1,0) [0|1] ""  DASy
 SG_ RFL_Obj06A_HeadingYawAngleVnce : 408|12@1+ (0.0003,0) [0|1] "rad^2"  DASy
 SG_ RFL_Obj06A_Dx : 40|13@1+ (0.0625,-256) [-256|255.9375] "m"  DASy
 SG_ RFL_Obj06A_LengthVnce : 420|12@1+ (0.01,0) [0|30] "m^2"  DASy
 SG_ RFL_Obj06A_WidthVnce : 432|12@1+ (0.01,0) [0|30] "m^2"  DASy
 SG_ RFL_Obj06A_HeightVnce : 444|12@1+ (0.01,0) [0|30] "m^2"  DASy
 SG_ RFL_Obj06A_ProbExist : 456|6@1+ (2,0) [0|100] "%"  DASy
 SG_ RFL_Obj06A_ProbObstacle : 462|6@1+ (2,0) [0|100] "%"  DASy
 SG_ RFL_Obj06A_ProbNonObstacle : 468|6@1+ (2,0) [0|100] "%"  DASy
 SG_ RFL_Obj06A_ProbMobileObst : 474|6@1+ (2,0) [0|100] "%"  DASy
 SG_ RFL_Obj06A_Dz : 53|6@1+ (0.25,-5) [-5|10.75] "m"  DASy
 SG_ RFL_Obj06A_Dy : 59|11@1+ (0.125,-128) [-128|127.875] "m"  DASy
 SG_ RFL_Obj06A_Valid : 70|1@1+ (1,0) [0|1] ""  DASy
 SG_ RFL_Obj06A_Vx : 71|12@1+ (0.0625,-128) [-128|127.9375] "m/s"  DASy
 SG_ RFL_Obj06A_Vy : 83|10@1+ (0.125,-64) [-64|63.875] "m/s"  DASy
 SG_ RFL_Obj06A_Ax : 93|10@1+ (0.03125,-16) [-16|15.96875] "m/s^2"  DASy

BO_ 541 RFL_Obj06B: 12 RadarFrontLeft
 SG_ RFL_Obj06B_CRC : 0|16@1+ (1,0) [0|65535] ""  DASy
 SG_ RFL_Obj06B_AliveCtr : 16|8@1+ (1,0) [0|255] ""  DASy
 SG_ RFL_Obj06B_ProtBlockCtr : 24|4@1+ (1,0) [0|15] ""  DASy
 SG_ RFL_Obj06B_ProbMob4PlusWhl : 28|6@1+ (2,0) [0|100] "%"  DASy
 SG_ RFL_Obj06B_ProbMob2Whl : 34|6@1+ (2,0) [0|100] "%"  DASy
 SG_ RFL_Obj06B_ProbMobPed : 40|6@1+ (2,0) [0|100] "%"  DASy
 SG_ RFL_Obj06B_Prob4PlusWhlCAR : 46|6@1+ (2,0) [0|100] "%"  DASy
 SG_ RFL_Obj06B_Prob4PlusWhlbHGV : 52|6@1+ (2,0) [0|100] "%"  DASy
 SG_ RFL_Obj06B_ProbGNDReflex : 58|6@1+ (2,0) [0|100] "%"  DASy
 SG_ RFL_Obj06B_ProbStatBarrier : 64|6@1+ (2,0) [0|100] "%"  DASy
 SG_ RFL_Obj06B_ProbStatObst : 70|6@1+ (2,0) [0|100] "%"  DASy
 SG_ RFL_Obj06B_MovingProbability : 76|6@1+ (2,0) [0|100] "%"  DASy
 SG_ RFL_Obj06B_MovingObserved : 82|6@1+ (2,0) [0|100] "%"  DASy
 SG_ RFL_Obj06B_BehaviorType : 88|3@1+ (1,0) [0|7] ""  DASy

BO_ 542 RFL_Obj07A: 64 RadarFrontLeft
 SG_ RFL_Obj07A_CRC : 0|16@1+ (1,0) [0|65535] ""  DASy
 SG_ RFL_Obj07A_Ay : 103|9@1+ (0.0625,-16) [-16|15.9375] "m/s^2"  DASy
 SG_ RFL_Obj07A_HeadingYawAngle : 112|9@1+ (0.0175,-4.48) [-3.15|3.15] "rad"  DASy
 SG_ RFL_Obj07A_Length : 121|7@1+ (0.125,0) [0|15.875] "m"  DASy
 SG_ RFL_Obj07A_Width : 128|7@1+ (0.125,0) [0|15.875] "m"  DASy
 SG_ RFL_Obj07A_Height : 135|7@1+ (0.125,0) [0|15.875] "m"  DASy
 SG_ RFL_Obj07A_DxVnce : 142|12@1+ (0.01,0) [0|30] "m^2"  DASy
 SG_ RFL_Obj07A_DyVnce : 154|12@1+ (0.01,0) [0|30] "m^2"  DASy
 SG_ RFL_Obj07A_DzVnce : 166|10@1+ (0.01,0) [0|10] "m^2"  DASy
 SG_ RFL_Obj07A_AliveCtr : 16|8@1+ (1,0) [0|255] ""  DASy
 SG_ RFL_Obj07A_VxVnce : 176|12@1+ (0.01,0) [0|30] "m^2/s^2"  DASy
 SG_ RFL_Obj07A_VyVnce : 188|12@1+ (0.01,0) [0|30] "m^2/s^2"  DASy
 SG_ RFL_Obj07A_AxVnce : 200|12@1+ (0.01,0) [0|30] "m^2/s^4"  DASy
 SG_ RFL_Obj07A_AyVnce : 212|12@1+ (0.01,0) [0|30] "m^2/s^4"  DASy
 SG_ RFL_Obj07A_RefPosIndex : 224|4@1+ (1,0) [0|15] ""  DASy
 SG_ RFL_Obj07A_DxDyCoVnce : 228|12@1+ (0.01,0) [0|30] "m^2"  DASy
 SG_ RFL_Obj07A_DxVxCoVnce : 240|12@1+ (0.01,0) [0|30] "m^2/s"  DASy
 SG_ RFL_Obj07A_ProtBlockCtr : 24|4@1+ (1,0) [0|15] ""  DASy
 SG_ RFL_Obj07A_DyVxCoVnce : 252|12@1+ (0.01,0) [0|30] "m^2/s"  DASy
 SG_ RFL_Obj07A_DxVyCoVnce : 264|12@1+ (0.01,0) [0|30] "m^2/s"  DASy
 SG_ RFL_Obj07A_DyVyCoVnce : 276|12@1+ (0.01,0) [0|30] "m^2/s"  DASy
 SG_ RFL_Obj07A_VxVyCoVnce : 288|12@1+ (0.01,0) [0|30] "m^2/s^2"  DASy
 SG_ RFL_Obj07A_DxAxCoVnce : 300|12@1+ (0.01,0) [0|30] "m^2/s^2"  DASy
 SG_ RFL_Obj07A_DyAxCoVnce : 312|12@1+ (0.01,0) [0|30] "m^2/s^2"  DASy
 SG_ RFL_Obj07A_VxAxCoVnce : 324|12@1+ (0.01,0) [0|30] "m^2/s^3"  DASy
 SG_ RFL_Obj07A_ID : 32|7@1+ (1,0) [0|127] ""  DASy
 SG_ RFL_Obj07A_VyAxCoVnce : 336|12@1+ (0.01,0) [0|30] "m^2/s^3"  DASy
 SG_ RFL_Obj07A_DxAyCoVnce : 348|12@1+ (0.01,0) [0|30] "m^2/s^2"  DASy
 SG_ RFL_Obj07A_DyAyCoVnce : 360|12@1+ (0.01,0) [0|30] "m^2/s^2"  DASy
 SG_ RFL_Obj07A_VxAyCoVnce : 372|12@1+ (0.01,0) [0|30] "m^2/s^3"  DASy
 SG_ RFL_Obj07A_VyAyCoVnce : 384|12@1+ (0.01,0) [0|30] "m^2/s^3"  DASy
 SG_ RFL_Obj07A_AxAyCoVnce : 396|12@1+ (0.01,0) [0|30] "m^2/s^4"  DASy
 SG_ RFL_Obj07A_Measured : 39|1@1+ (1,0) [0|1] ""  DASy
 SG_ RFL_Obj07A_HeadingYawAngleVnce : 408|12@1+ (0.0003,0) [0|1] "rad^2"  DASy
 SG_ RFL_Obj07A_Dx : 40|13@1+ (0.0625,-256) [-256|255.9375] "m"  DASy
 SG_ RFL_Obj07A_LengthVnce : 420|12@1+ (0.01,0) [0|30] "m^2"  DASy
 SG_ RFL_Obj07A_WidthVnce : 432|12@1+ (0.01,0) [0|30] "m^2"  DASy
 SG_ RFL_Obj07A_HeightVnce : 444|12@1+ (0.01,0) [0|30] "m^2"  DASy
 SG_ RFL_Obj07A_ProbExist : 456|6@1+ (2,0) [0|100] "%"  DASy
 SG_ RFL_Obj07A_ProbObstacle : 462|6@1+ (2,0) [0|100] "%"  DASy
 SG_ RFL_Obj07A_ProbNonObstacle : 468|6@1+ (2,0) [0|100] "%"  DASy
 SG_ RFL_Obj07A_ProbMobileObst : 474|6@1+ (2,0) [0|100] "%"  DASy
 SG_ RFL_Obj07A_Dz : 53|6@1+ (0.25,-5) [-5|10.75] "m"  DASy
 SG_ RFL_Obj07A_Dy : 59|11@1+ (0.125,-128) [-128|127.875] "m"  DASy
 SG_ RFL_Obj07A_Valid : 70|1@1+ (1,0) [0|1] ""  DASy
 SG_ RFL_Obj07A_Vx : 71|12@1+ (0.0625,-128) [-128|127.9375] "m/s"  DASy
 SG_ RFL_Obj07A_Vy : 83|10@1+ (0.125,-64) [-64|63.875] "m/s"  DASy
 SG_ RFL_Obj07A_Ax : 93|10@1+ (0.03125,-16) [-16|15.96875] "m/s^2"  DASy

BO_ 543 RFL_Obj07B: 12 RadarFrontLeft
 SG_ RFL_Obj07B_CRC : 0|16@1+ (1,0) [0|65535] ""  DASy
 SG_ RFL_Obj07B_AliveCtr : 16|8@1+ (1,0) [0|255] ""  DASy
 SG_ RFL_Obj07B_ProtBlockCtr : 24|4@1+ (1,0) [0|15] ""  DASy
 SG_ RFL_Obj07B_ProbMob4PlusWhl : 28|6@1+ (2,0) [0|100] "%"  DASy
 SG_ RFL_Obj07B_ProbMob2Whl : 34|6@1+ (2,0) [0|100] "%"  DASy
 SG_ RFL_Obj07B_ProbMobPed : 40|6@1+ (2,0) [0|100] "%"  DASy
 SG_ RFL_Obj07B_Prob4PlusWhlCAR : 46|6@1+ (2,0) [0|100] "%"  DASy
 SG_ RFL_Obj07B_Prob4PlusWhlbHGV : 52|6@1+ (2,0) [0|100] "%"  DASy
 SG_ RFL_Obj07B_ProbGNDReflex : 58|6@1+ (2,0) [0|100] "%"  DASy
 SG_ RFL_Obj07B_ProbStatBarrier : 64|6@1+ (2,0) [0|100] "%"  DASy
 SG_ RFL_Obj07B_ProbStatObst : 70|6@1+ (2,0) [0|100] "%"  DASy
 SG_ RFL_Obj07B_MovingProbability : 76|6@1+ (2,0) [0|100] "%"  DASy
 SG_ RFL_Obj07B_MovingObserved : 82|6@1+ (2,0) [0|100] "%"  DASy
 SG_ RFL_Obj07B_BehaviorType : 88|3@1+ (1,0) [0|7] ""  DASy

BO_ 544 RFL_Obj08A: 64 RadarFrontLeft
 SG_ RFL_Obj08A_CRC : 0|16@1+ (1,0) [0|65535] ""  DASy
 SG_ RFL_Obj08A_Ay : 103|9@1+ (0.0625,-16) [-16|15.9375] "m/s^2"  DASy
 SG_ RFL_Obj08A_HeadingYawAngle : 112|9@1+ (0.0175,-4.48) [-3.15|3.15] "rad"  DASy
 SG_ RFL_Obj08A_Length : 121|7@1+ (0.125,0) [0|15.875] "m"  DASy
 SG_ RFL_Obj08A_Width : 128|7@1+ (0.125,0) [0|15.875] "m"  DASy
 SG_ RFL_Obj08A_Height : 135|7@1+ (0.125,0) [0|15.875] "m"  DASy
 SG_ RFL_Obj08A_DxVnce : 142|12@1+ (0.01,0) [0|30] "m^2"  DASy
 SG_ RFL_Obj08A_DyVnce : 154|12@1+ (0.01,0) [0|30] "m^2"  DASy
 SG_ RFL_Obj08A_DzVnce : 166|10@1+ (0.01,0) [0|10] "m^2"  DASy
 SG_ RFL_Obj08A_AliveCtr : 16|8@1+ (1,0) [0|255] ""  DASy
 SG_ RFL_Obj08A_VxVnce : 176|12@1+ (0.01,0) [0|30] "m^2/s^2"  DASy
 SG_ RFL_Obj08A_VyVnce : 188|12@1+ (0.01,0) [0|30] "m^2/s^2"  DASy
 SG_ RFL_Obj08A_AxVnce : 200|12@1+ (0.01,0) [0|30] "m^2/s^4"  DASy
 SG_ RFL_Obj08A_AyVnce : 212|12@1+ (0.01,0) [0|30] "m^2/s^4"  DASy
 SG_ RFL_Obj08A_RefPosIndex : 224|4@1+ (1,0) [0|15] ""  DASy
 SG_ RFL_Obj08A_DxDyCoVnce : 228|12@1+ (0.01,0) [0|30] "m^2"  DASy
 SG_ RFL_Obj08A_DxVxCoVnce : 240|12@1+ (0.01,0) [0|30] "m^2/s"  DASy
 SG_ RFL_Obj08A_ProtBlockCtr : 24|4@1+ (1,0) [0|15] ""  DASy
 SG_ RFL_Obj08A_DyVxCoVnce : 252|12@1+ (0.01,0) [0|30] "m^2/s"  DASy
 SG_ RFL_Obj08A_DxVyCoVnce : 264|12@1+ (0.01,0) [0|30] "m^2/s"  DASy
 SG_ RFL_Obj08A_DyVyCoVnce : 276|12@1+ (0.01,0) [0|30] "m^2/s"  DASy
 SG_ RFL_Obj08A_VxVyCoVnce : 288|12@1+ (0.01,0) [0|30] "m^2/s^2"  DASy
 SG_ RFL_Obj08A_DxAxCoVnce : 300|12@1+ (0.01,0) [0|30] "m^2/s^2"  DASy
 SG_ RFL_Obj08A_DyAxCoVnce : 312|12@1+ (0.01,0) [0|30] "m^2/s^2"  DASy
 SG_ RFL_Obj08A_VxAxCoVnce : 324|12@1+ (0.01,0) [0|30] "m^2/s^3"  DASy
 SG_ RFL_Obj08A_ID : 32|7@1+ (1,0) [0|127] ""  DASy
 SG_ RFL_Obj08A_VyAxCoVnce : 336|12@1+ (0.01,0) [0|30] "m^2/s^3"  DASy
 SG_ RFL_Obj08A_DxAyCoVnce : 348|12@1+ (0.01,0) [0|30] "m^2/s^2"  DASy
 SG_ RFL_Obj08A_DyAyCoVnce : 360|12@1+ (0.01,0) [0|30] "m^2/s^2"  DASy
 SG_ RFL_Obj08A_VxAyCoVnce : 372|12@1+ (0.01,0) [0|30] "m^2/s^3"  DASy
 SG_ RFL_Obj08A_VyAyCoVnce : 384|12@1+ (0.01,0) [0|30] "m^2/s^3"  DASy
 SG_ RFL_Obj08A_AxAyCoVnce : 396|12@1+ (0.01,0) [0|30] "m^2/s^4"  DASy
 SG_ RFL_Obj08A_Measured : 39|1@1+ (1,0) [0|1] ""  DASy
 SG_ RFL_Obj08A_HeadingYawAngleVnce : 408|12@1+ (0.0003,0) [0|1] "rad^2"  DASy
 SG_ RFL_Obj08A_Dx : 40|13@1+ (0.0625,-256) [-256|255.9375] "m"  DASy
 SG_ RFL_Obj08A_LengthVnce : 420|12@1+ (0.01,0) [0|30] "m^2"  DASy
 SG_ RFL_Obj08A_WidthVnce : 432|12@1+ (0.01,0) [0|30] "m^2"  DASy
 SG_ RFL_Obj08A_HeightVnce : 444|12@1+ (0.01,0) [0|30] "m^2"  DASy
 SG_ RFL_Obj08A_ProbExist : 456|6@1+ (2,0) [0|100] "%"  DASy
 SG_ RFL_Obj08A_ProbObstacle : 462|6@1+ (2,0) [0|100] "%"  DASy
 SG_ RFL_Obj08A_ProbNonObstacle : 468|6@1+ (2,0) [0|100] "%"  DASy
 SG_ RFL_Obj08A_ProbMobileObst : 474|6@1+ (2,0) [0|100] "%"  DASy
 SG_ RFL_Obj08A_Dz : 53|6@1+ (0.25,-5) [-5|10.75] "m"  DASy
 SG_ RFL_Obj08A_Dy : 59|11@1+ (0.125,-128) [-128|127.875] "m"  DASy
 SG_ RFL_Obj08A_Valid : 70|1@1+ (1,0) [0|1] ""  DASy
 SG_ RFL_Obj08A_Vx : 71|12@1+ (0.0625,-128) [-128|127.9375] "m/s"  DASy
 SG_ RFL_Obj08A_Vy : 83|10@1+ (0.125,-64) [-64|63.875] "m/s"  DASy
 SG_ RFL_Obj08A_Ax : 93|10@1+ (0.03125,-16) [-16|15.96875] "m/s^2"  DASy

BO_ 545 RFL_Obj08B: 12 RadarFrontLeft
 SG_ RFL_Obj08B_CRC : 0|16@1+ (1,0) [0|65535] ""  DASy
 SG_ RFL_Obj08B_AliveCtr : 16|8@1+ (1,0) [0|255] ""  DASy
 SG_ RFL_Obj08B_ProtBlockCtr : 24|4@1+ (1,0) [0|15] ""  DASy
 SG_ RFL_Obj08B_ProbMob4PlusWhl : 28|6@1+ (2,0) [0|100] "%"  DASy
 SG_ RFL_Obj08B_ProbMob2Whl : 34|6@1+ (2,0) [0|100] "%"  DASy
 SG_ RFL_Obj08B_ProbMobPed : 40|6@1+ (2,0) [0|100] "%"  DASy
 SG_ RFL_Obj08B_Prob4PlusWhlCAR : 46|6@1+ (2,0) [0|100] "%"  DASy
 SG_ RFL_Obj08B_Prob4PlusWhlbHGV : 52|6@1+ (2,0) [0|100] "%"  DASy
 SG_ RFL_Obj08B_ProbGNDReflex : 58|6@1+ (2,0) [0|100] "%"  DASy
 SG_ RFL_Obj08B_ProbStatBarrier : 64|6@1+ (2,0) [0|100] "%"  DASy
 SG_ RFL_Obj08B_ProbStatObst : 70|6@1+ (2,0) [0|100] "%"  DASy
 SG_ RFL_Obj08B_MovingProbability : 76|6@1+ (2,0) [0|100] "%"  DASy
 SG_ RFL_Obj08B_MovingObserved : 82|6@1+ (2,0) [0|100] "%"  DASy
 SG_ RFL_Obj08B_BehaviorType : 88|3@1+ (1,0) [0|7] ""  DASy

BO_ 546 RFL_Obj09A: 64 RadarFrontLeft
 SG_ RFL_Obj09A_CRC : 0|16@1+ (1,0) [0|65535] ""  DASy
 SG_ RFL_Obj09A_Ay : 103|9@1+ (0.0625,-16) [-16|15.9375] "m/s^2"  DASy
 SG_ RFL_Obj09A_HeadingYawAngle : 112|9@1+ (0.0175,-4.48) [-3.15|3.15] "rad"  DASy
 SG_ RFL_Obj09A_Length : 121|7@1+ (0.125,0) [0|15.875] "m"  DASy
 SG_ RFL_Obj09A_Width : 128|7@1+ (0.125,0) [0|15.875] "m"  DASy
 SG_ RFL_Obj09A_Height : 135|7@1+ (0.125,0) [0|15.875] "m"  DASy
 SG_ RFL_Obj09A_DxVnce : 142|12@1+ (0.01,0) [0|30] "m^2"  DASy
 SG_ RFL_Obj09A_DyVnce : 154|12@1+ (0.01,0) [0|30] "m^2"  DASy
 SG_ RFL_Obj09A_DzVnce : 166|10@1+ (0.01,0) [0|10] "m^2"  DASy
 SG_ RFL_Obj09A_AliveCtr : 16|8@1+ (1,0) [0|255] ""  DASy
 SG_ RFL_Obj09A_VxVnce : 176|12@1+ (0.01,0) [0|30] "m^2/s^2"  DASy
 SG_ RFL_Obj09A_VyVnce : 188|12@1+ (0.01,0) [0|30] "m^2/s^2"  DASy
 SG_ RFL_Obj09A_AxVnce : 200|12@1+ (0.01,0) [0|30] "m^2/s^4"  DASy
 SG_ RFL_Obj09A_AyVnce : 212|12@1+ (0.01,0) [0|30] "m^2/s^4"  DASy
 SG_ RFL_Obj09A_RefPosIndex : 224|4@1+ (1,0) [0|15] ""  DASy
 SG_ RFL_Obj09A_DxDyCoVnce : 228|12@1+ (0.01,0) [0|30] "m^2"  DASy
 SG_ RFL_Obj09A_DxVxCoVnce : 240|12@1+ (0.01,0) [0|30] "m^2/s"  DASy
 SG_ RFL_Obj09A_ProtBlockCtr : 24|4@1+ (1,0) [0|15] ""  DASy
 SG_ RFL_Obj09A_DyVxCoVnce : 252|12@1+ (0.01,0) [0|30] "m^2/s"  DASy
 SG_ RFL_Obj09A_DxVyCoVnce : 264|12@1+ (0.01,0) [0|30] "m^2/s"  DASy
 SG_ RFL_Obj09A_DyVyCoVnce : 276|12@1+ (0.01,0) [0|30] "m^2/s"  DASy
 SG_ RFL_Obj09A_VxVyCoVnce : 288|12@1+ (0.01,0) [0|30] "m^2/s^2"  DASy
 SG_ RFL_Obj09A_DxAxCoVnce : 300|12@1+ (0.01,0) [0|30] "m^2/s^2"  DASy
 SG_ RFL_Obj09A_DyAxCoVnce : 312|12@1+ (0.01,0) [0|30] "m^2/s^2"  DASy
 SG_ RFL_Obj09A_VxAxCoVnce : 324|12@1+ (0.01,0) [0|30] "m^2/s^3"  DASy
 SG_ RFL_Obj09A_ID : 32|7@1+ (1,0) [0|127] ""  DASy
 SG_ RFL_Obj09A_VyAxCoVnce : 336|12@1+ (0.01,0) [0|30] "m^2/s^3"  DASy
 SG_ RFL_Obj09A_DxAyCoVnce : 348|12@1+ (0.01,0) [0|30] "m^2/s^2"  DASy
 SG_ RFL_Obj09A_DyAyCoVnce : 360|12@1+ (0.01,0) [0|30] "m^2/s^2"  DASy
 SG_ RFL_Obj09A_VxAyCoVnce : 372|12@1+ (0.01,0) [0|30] "m^2/s^3"  DASy
 SG_ RFL_Obj09A_VyAyCoVnce : 384|12@1+ (0.01,0) [0|30] "m^2/s^3"  DASy
 SG_ RFL_Obj09A_AxAyCoVnce : 396|12@1+ (0.01,0) [0|30] "m^2/s^4"  DASy
 SG_ RFL_Obj09A_Measured : 39|1@1+ (1,0) [0|1] ""  DASy
 SG_ RFL_Obj09A_HeadingYawAngleVnce : 408|12@1+ (0.0003,0) [0|1] "rad^2"  DASy
 SG_ RFL_Obj09A_Dx : 40|13@1+ (0.0625,-256) [-256|255.9375] "m"  DASy
 SG_ RFL_Obj09A_LengthVnce : 420|12@1+ (0.01,0) [0|30] "m^2"  DASy
 SG_ RFL_Obj09A_WidthVnce : 432|12@1+ (0.01,0) [0|30] "m^2"  DASy
 SG_ RFL_Obj09A_HeightVnce : 444|12@1+ (0.01,0) [0|30] "m^2"  DASy
 SG_ RFL_Obj09A_ProbExist : 456|6@1+ (2,0) [0|100] "%"  DASy
 SG_ RFL_Obj09A_ProbObstacle : 462|6@1+ (2,0) [0|100] "%"  DASy
 SG_ RFL_Obj09A_ProbNonObstacle : 468|6@1+ (2,0) [0|100] "%"  DASy
 SG_ RFL_Obj09A_ProbMobileObst : 474|6@1+ (2,0) [0|100] "%"  DASy
 SG_ RFL_Obj09A_Dz : 53|6@1+ (0.25,-5) [-5|10.75] "m"  DASy
 SG_ RFL_Obj09A_Dy : 59|11@1+ (0.125,-128) [-128|127.875] "m"  DASy
 SG_ RFL_Obj09A_Valid : 70|1@1+ (1,0) [0|1] ""  DASy
 SG_ RFL_Obj09A_Vx : 71|12@1+ (0.0625,-128) [-128|127.9375] "m/s"  DASy
 SG_ RFL_Obj09A_Vy : 83|10@1+ (0.125,-64) [-64|63.875] "m/s"  DASy
 SG_ RFL_Obj09A_Ax : 93|10@1+ (0.03125,-16) [-16|15.96875] "m/s^2"  DASy

BO_ 547 RFL_Obj09B: 12 RadarFrontLeft
 SG_ RFL_Obj09B_CRC : 0|16@1+ (1,0) [0|65535] ""  DASy
 SG_ RFL_Obj09B_AliveCtr : 16|8@1+ (1,0) [0|255] ""  DASy
 SG_ RFL_Obj09B_ProtBlockCtr : 24|4@1+ (1,0) [0|15] ""  DASy
 SG_ RFL_Obj09B_ProbMob4PlusWhl : 28|6@1+ (2,0) [0|100] "%"  DASy
 SG_ RFL_Obj09B_ProbMob2Whl : 34|6@1+ (2,0) [0|100] "%"  DASy
 SG_ RFL_Obj09B_ProbMobPed : 40|6@1+ (2,0) [0|100] "%"  DASy
 SG_ RFL_Obj09B_Prob4PlusWhlCAR : 46|6@1+ (2,0) [0|100] "%"  DASy
 SG_ RFL_Obj09B_Prob4PlusWhlbHGV : 52|6@1+ (2,0) [0|100] "%"  DASy
 SG_ RFL_Obj09B_ProbGNDReflex : 58|6@1+ (2,0) [0|100] "%"  DASy
 SG_ RFL_Obj09B_ProbStatBarrier : 64|6@1+ (2,0) [0|100] "%"  DASy
 SG_ RFL_Obj09B_ProbStatObst : 70|6@1+ (2,0) [0|100] "%"  DASy
 SG_ RFL_Obj09B_MovingProbability : 76|6@1+ (2,0) [0|100] "%"  DASy
 SG_ RFL_Obj09B_MovingObserved : 82|6@1+ (2,0) [0|100] "%"  DASy
 SG_ RFL_Obj09B_BehaviorType : 88|3@1+ (1,0) [0|7] ""  DASy

CM_ BO_ 3221225472 "This is a message for not used signals, created by Vector CANdb++ DBC OLE DB Provider.";
CM_ SG_ 63 CMRR_FL_E2E_CheckSum "CRC - Autosar E2E Profile 1";
CM_ SG_ 63 CMRR_FL_E2E_AliveCounter "Alive counter - Autosar E2E Profile 1";
CM_ SG_ 63 CMRR_FL_DecelReq "FCTB braking request";
CM_ SG_ 63 CMRR_FL_Lvl_HBA "FCTB HBA level";
CM_ SG_ 63 CMRR_FL_Req_HBA "FCTB HBA request";
CM_ SG_ 63 CMRR_FL_Req_Prefill "FCTB prefill request";
CM_ SG_ 63 CMRR_FL_Decel_FCTB "FCTB requested deceleration";
CM_ SG_ 76 RFR_FctSwtFb_CRC "CRC";
CM_ SG_ 76 RFR_FctSwtFb_AliveCtr "Alive Counter - E2E profile 5";
CM_ SG_ 76 RFR_FCTASwtFb "FCTA switch";
CM_ SG_ 76 RFR_FCTBSwtFb "FCTB switch";
CM_ SG_ 82 RFL_Status_CRC "CRC - Autosar E2E Profile TBD
for BJEV it is Profile 1 based, same with public CAN E2E-- Alive Counter 0-14";
CM_ SG_ 82 RFL_Status_AliveCtr "Alive counter - Autosar E2E Profile TBD
for BJEV it is Profile 1 based, same with public CAN E2E-- Alive Counter 0-14";
CM_ SG_ 82 RFL_Status_SensorState "The sensor shall provide its operation state.
In case of multiple errors the most severe state shall be sent.
This signal is used for safety and time-out check purposes";
CM_ SG_ 86 RFR_Status_CRC "CRC - Autosar E2E Profile TBD
for BJEV it is Profile 1 based, same with public CAN E2E-- Alive Counter 0-14";
CM_ SG_ 86 RFR_Status_AliveCtr "Alive counter - Autosar E2E Profile TBD
for BJEV it is Profile 1 based, same with public CAN E2E-- Alive Counter 0-14";
CM_ SG_ 86 RFR_Status_SensorState "The sensor shall provide its operation state.
In case of multiple errors the most severe state shall be sent.
This signal is used for safety and time-out check purposes";
CM_ SG_ 517 RFL_ObjHdr_CRC "CRC - Autosar E2E Profile 5";
CM_ SG_ 517 RFL_ObjHdr_MountPosY "mount offset of sensor in lateral direction relative to mid axis of vehicle";
CM_ SG_ 517 RFL_ObjHdr_MountPosX "mount offset of sensor in longitudinal direction relative to rear axis of vehicle";
CM_ SG_ 517 RFL_ObjHdr_MountPosZ "mount offset of sensor in elevation direction relative to GROUND";
CM_ SG_ 517 RFL_ObjHdr_ObjectDownSel "the detected number of objects exceeded the number of max. objects that can be transmitted";
CM_ SG_ 517 RFL_ObjHdr_YawMountAngle "angle between sensor mounting direction and vehicle longitudinal axis, Azimuth";
CM_ SG_ 517 RFL_ObjHdr_YawAngleLower "Lower angle of the fied of view Azimuth";
CM_ SG_ 517 RFL_ObjHdr_AliveCtr "Alive counter - Autosar E2E Profile 5";
CM_ SG_ 517 RFL_ObjHdr_AziOutOfSpec "The sensor was detected to be out-of-spec due to misalignment in azimuth";
CM_ SG_ 517 RFL_ObjHdr_YawAngleUpper "Upper angle of the field of view Azimuth";
CM_ SG_ 517 RFL_ObjHdr_ElevOutOfSpec "The sensor was detected to be out-of-spec due to misalignment in elevation";
CM_ SG_ 517 RFL_ObjHdr_PitchMountAngle "angle between sensor mounting direction and vehicle longitudinal axis, Elevation";
CM_ SG_ 517 RFL_ObjHdr_PitchAngleLower "Lower angle of the fied of view Elevation";
CM_ SG_ 517 RFL_ObjHdr_PitchAngleUpper "Upper angle of the field of view Elevation";
CM_ SG_ 517 RFL_ObjHdr_RollMountAngle "Tilt of the mounting sensor";
CM_ SG_ 517 RFL_ObjHdr_DetectionRange "Estimated detection range of the sensor";
CM_ SG_ 517 RFL_ObjHdr_ProtBlockCtr "Protocol-Signal: Block-Counter";
CM_ SG_ 517 RFL_ObjHdr_SensorState "The sensor shall provide its operation state.
In case of multiple errors the most severe state shall be sent.";
CM_ SG_ 517 RFL_ObjHdr_ProtocolVersion "Protocol version to be send: 0x0105 = V1.5";
CM_ SG_ 517 RFL_ObjHdr_ProtObjectCount "number of detected VALID Objects that have been sent to the bus";
CM_ SG_ 517 RFL_ObjHdr_TimeStampStatus "Autosar StbM_TimeBaseStatusType bitfield with extension:
Bit 0: TIMEOUT
Bit 1: Reserved1
Bit 2: SYNC_TO_GATEWAY
Bit 3: GLOBAL_TIME_BASE
Bit 4: TIMELEAP_FUTURE
Bit 5: TIMELEAP_PAST
Bit 6: Reserved6
Bit 7: Extension: GENERAL_ERROR";
CM_ SG_ 517 RFL_ObjHdr_TimeStamp "Time Stamp";
CM_ SG_ 528 RFL_Obj00A_CRC "CRC - Autosar E2E Profile 5";
CM_ SG_ 528 RFL_Obj00A_Ay "Object relative acceleration in Y direction";
CM_ SG_ 528 RFL_Obj00A_HeadingYawAngle "Object heading yaw angle";
CM_ SG_ 528 RFL_Obj00A_Length "Object Length";
CM_ SG_ 528 RFL_Obj00A_Width "Object Width";
CM_ SG_ 528 RFL_Obj00A_Height "Object Height";
CM_ SG_ 528 RFL_Obj00A_DxVnce "Variance of object position in X direction";
CM_ SG_ 528 RFL_Obj00A_DyVnce "Variance of object position in Y direction";
CM_ SG_ 528 RFL_Obj00A_DzVnce "Variance of object position in Z direction";
CM_ SG_ 528 RFL_Obj00A_AliveCtr "Alive counter - Autosar E2E Profile 5";
CM_ SG_ 528 RFL_Obj00A_VxVnce "Variance of object relative velocity in X direction";
CM_ SG_ 528 RFL_Obj00A_VyVnce "Variance of object relative velocity in Y direction";
CM_ SG_ 528 RFL_Obj00A_AxVnce "Variance of object relative acceleration in X direction";
CM_ SG_ 528 RFL_Obj00A_AyVnce "Variance of object relative acceleration in Y direction";
CM_ SG_ 528 RFL_Obj00A_RefPosIndex "Reference Position of the detected objects";
CM_ SG_ 528 RFL_Obj00A_DxDyCoVnce "Covariance of Dx and Dy";
CM_ SG_ 528 RFL_Obj00A_DxVxCoVnce "Covariance of Dx and Vx";
CM_ SG_ 528 RFL_Obj00A_ProtBlockCtr "Protocol-Signal: Block-Counter";
CM_ SG_ 528 RFL_Obj00A_DyVxCoVnce "Covariance of Dy and Ax";
CM_ SG_ 528 RFL_Obj00A_DxVyCoVnce "Covariance of Dx and Vy";
CM_ SG_ 528 RFL_Obj00A_DyVyCoVnce "Covariance of Dy and Vy";
CM_ SG_ 528 RFL_Obj00A_VxVyCoVnce "Covariance of Vx and Vy";
CM_ SG_ 528 RFL_Obj00A_DxAxCoVnce "Covariance of Dx and Ax";
CM_ SG_ 528 RFL_Obj00A_DyAxCoVnce "Covariance of Dy and Ax";
CM_ SG_ 528 RFL_Obj00A_VxAxCoVnce "Covariance of Vx and Ax";
CM_ SG_ 528 RFL_Obj00A_ID "Unique Object ID";
CM_ SG_ 528 RFL_Obj00A_VyAxCoVnce "Covariance of Vy and Ax";
CM_ SG_ 528 RFL_Obj00A_DxAyCoVnce "Covariance of Dx and Ay";
CM_ SG_ 528 RFL_Obj00A_DyAyCoVnce "Covariance of Dy and Ay";
CM_ SG_ 528 RFL_Obj00A_VxAyCoVnce "Covariance of Vx and Ay";
CM_ SG_ 528 RFL_Obj00A_VyAyCoVnce "Covariance of Vy and Ay";
CM_ SG_ 528 RFL_Obj00A_AxAyCoVnce "Covariance of Ax and Ay";
CM_ SG_ 528 RFL_Obj00A_Measured "Object is measured or not";
CM_ SG_ 528 RFL_Obj00A_HeadingYawAngleVnce "Variance of object heading yaw angle";
CM_ SG_ 528 RFL_Obj00A_Dx "Object position in X direction";
CM_ SG_ 528 RFL_Obj00A_LengthVnce "Variance of object Length";
CM_ SG_ 528 RFL_Obj00A_WidthVnce "Variance of object Width";
CM_ SG_ 528 RFL_Obj00A_HeightVnce "Variance of object Height";
CM_ SG_ 528 RFL_Obj00A_ProbExist "Existence probability of object";
CM_ SG_ 528 RFL_Obj00A_ProbObstacle "Probability of the object being an Obstacle";
CM_ SG_ 528 RFL_Obj00A_ProbNonObstacle "Probability of the object being a Non-Obstacle";
CM_ SG_ 528 RFL_Obj00A_ProbMobileObst "Probability of the object being a mobile obstacle";
CM_ SG_ 528 RFL_Obj00A_Dz "Object position in Z direction";
CM_ SG_ 528 RFL_Obj00A_Dy "Object position in Y direction";
CM_ SG_ 528 RFL_Obj00A_Valid "Object is valid or not";
CM_ SG_ 528 RFL_Obj00A_Vx "Object relative velocity in X direction";
CM_ SG_ 528 RFL_Obj00A_Vy "Object relative velocity in Y direction";
CM_ SG_ 528 RFL_Obj00A_Ax "Object relative acceleration in X direction";
CM_ SG_ 529 RFL_Obj00B_CRC "CRC - Autosar E2E Profile 5";
CM_ SG_ 529 RFL_Obj00B_AliveCtr "Alive counter - Autosar E2E Profile 5";
CM_ SG_ 529 RFL_Obj00B_ProtBlockCtr "Protocol-Signal: Block-Counter";
CM_ SG_ 529 RFL_Obj00B_ProbMob4PlusWhl "Probability of a mobile object which has 4 or more wheels";
CM_ SG_ 529 RFL_Obj00B_ProbMob2Whl "Probability of a mobile object being 2-wheels vehicle";
CM_ SG_ 529 RFL_Obj00B_ProbMobPed "Probability of a mobile object being a pedestrian";
CM_ SG_ 529 RFL_Obj00B_Prob4PlusWhlCAR "Probability of a mobile object which has 4 or more wheels--passenger car";
CM_ SG_ 529 RFL_Obj00B_Prob4PlusWhlbHGV "Probability of a mobile object which has 4 or more wheels--commercial vehicle (Truck)";
CM_ SG_ 529 RFL_Obj00B_ProbGNDReflex "Probability of the object being a ground reflex";
CM_ SG_ 529 RFL_Obj00B_ProbStatBarrier "Probability of the object being a stationary road barrier";
CM_ SG_ 529 RFL_Obj00B_ProbStatObst "Probability of the object being a stationary obstacle";
CM_ SG_ 529 RFL_Obj00B_MovingProbability "Object has been observed moving over the ground";
CM_ SG_ 529 RFL_Obj00B_MovingObserved "Object has been observed moving over the ground since it was first detected";
CM_ SG_ 529 RFL_Obj00B_BehaviorType "Indicates that which behavior the object associated for";
CM_ SG_ 530 RFL_Obj01A_CRC "CRC - Autosar E2E Profile 5";
CM_ SG_ 530 RFL_Obj01A_Ay "Object relative acceleration in Y direction";
CM_ SG_ 530 RFL_Obj01A_HeadingYawAngle "Object heading yaw angle";
CM_ SG_ 530 RFL_Obj01A_Length "Object Length";
CM_ SG_ 530 RFL_Obj01A_Width "Object Width";
CM_ SG_ 530 RFL_Obj01A_Height "Object Height";
CM_ SG_ 530 RFL_Obj01A_DxVnce "Variance of object position in X direction";
CM_ SG_ 530 RFL_Obj01A_DyVnce "Variance of object position in Y direction";
CM_ SG_ 530 RFL_Obj01A_DzVnce "Variance of object position in Z direction";
CM_ SG_ 530 RFL_Obj01A_AliveCtr "Alive counter - Autosar E2E Profile 5";
CM_ SG_ 530 RFL_Obj01A_VxVnce "Variance of object relative velocity in X direction";
CM_ SG_ 530 RFL_Obj01A_VyVnce "Variance of object relative velocity in Y direction";
CM_ SG_ 530 RFL_Obj01A_AxVnce "Variance of object relative acceleration in X direction";
CM_ SG_ 530 RFL_Obj01A_AyVnce "Variance of object relative acceleration in Y direction";
CM_ SG_ 530 RFL_Obj01A_RefPosIndex "Reference Position of the detected objects";
CM_ SG_ 530 RFL_Obj01A_DxDyCoVnce "Covariance of Dx and Dy";
CM_ SG_ 530 RFL_Obj01A_DxVxCoVnce "Covariance of Dx and Vx";
CM_ SG_ 530 RFL_Obj01A_ProtBlockCtr "Protocol-Signal: Block-Counter";
CM_ SG_ 530 RFL_Obj01A_DyVxCoVnce "Covariance of Dy and Ax";
CM_ SG_ 530 RFL_Obj01A_DxVyCoVnce "Covariance of Dx and Vy";
CM_ SG_ 530 RFL_Obj01A_DyVyCoVnce "Covariance of Dy and Vy";
CM_ SG_ 530 RFL_Obj01A_VxVyCoVnce "Covariance of Vx and Vy";
CM_ SG_ 530 RFL_Obj01A_DxAxCoVnce "Covariance of Dx and Ax";
CM_ SG_ 530 RFL_Obj01A_DyAxCoVnce "Covariance of Dy and Ax";
CM_ SG_ 530 RFL_Obj01A_VxAxCoVnce "Covariance of Vx and Ax";
CM_ SG_ 530 RFL_Obj01A_ID "Unique Object ID";
CM_ SG_ 530 RFL_Obj01A_VyAxCoVnce "Covariance of Vy and Ax";
CM_ SG_ 530 RFL_Obj01A_DxAyCoVnce "Covariance of Dx and Ay";
CM_ SG_ 530 RFL_Obj01A_DyAyCoVnce "Covariance of Dy and Ay";
CM_ SG_ 530 RFL_Obj01A_VxAyCoVnce "Covariance of Vx and Ay";
CM_ SG_ 530 RFL_Obj01A_VyAyCoVnce "Covariance of Vy and Ay";
CM_ SG_ 530 RFL_Obj01A_AxAyCoVnce "Covariance of Ax and Ay";
CM_ SG_ 530 RFL_Obj01A_Measured "Object is measured or not";
CM_ SG_ 530 RFL_Obj01A_HeadingYawAngleVnce "Variance of object heading yaw angle";
CM_ SG_ 530 RFL_Obj01A_Dx "Object position in X direction";
CM_ SG_ 530 RFL_Obj01A_LengthVnce "Variance of object Length";
CM_ SG_ 530 RFL_Obj01A_WidthVnce "Variance of object Width";
CM_ SG_ 530 RFL_Obj01A_HeightVnce "Variance of object Height";
CM_ SG_ 530 RFL_Obj01A_ProbExist "Existence probability of object";
CM_ SG_ 530 RFL_Obj01A_ProbObstacle "Probability of the object being an Obstacle";
CM_ SG_ 530 RFL_Obj01A_ProbNonObstacle "Probability of the object being a Non-Obstacle";
CM_ SG_ 530 RFL_Obj01A_ProbMobileObst "Probability of the object being a mobile obstacle";
CM_ SG_ 530 RFL_Obj01A_Dz "Object position in Z direction";
CM_ SG_ 530 RFL_Obj01A_Dy "Object position in Y direction";
CM_ SG_ 530 RFL_Obj01A_Valid "Object is valid or not";
CM_ SG_ 530 RFL_Obj01A_Vx "Object relative velocity in X direction";
CM_ SG_ 530 RFL_Obj01A_Vy "Object relative velocity in Y direction";
CM_ SG_ 530 RFL_Obj01A_Ax "Object relative acceleration in X direction";
CM_ SG_ 531 RFL_Obj01B_CRC "CRC - Autosar E2E Profile 5";
CM_ SG_ 531 RFL_Obj01B_AliveCtr "Alive counter - Autosar E2E Profile 5";
CM_ SG_ 531 RFL_Obj01B_ProtBlockCtr "Protocol-Signal: Block-Counter";
CM_ SG_ 531 RFL_Obj01B_ProbMob4PlusWhl "Probability of a mobile object which has 4 or more wheels";
CM_ SG_ 531 RFL_Obj01B_ProbMob2Whl "Probability of a mobile object being 2-wheels vehicle";
CM_ SG_ 531 RFL_Obj01B_ProbMobPed "Probability of a mobile object being a pedestrian";
CM_ SG_ 531 RFL_Obj01B_Prob4PlusWhlCAR "Probability of a mobile object which has 4 or more wheels--passenger car";
CM_ SG_ 531 RFL_Obj01B_Prob4PlusWhlbHGV "Probability of a mobile object which has 4 or more wheels--commercial vehicle (Truck)";
CM_ SG_ 531 RFL_Obj01B_ProbGNDReflex "Probability of the object being a ground reflex";
CM_ SG_ 531 RFL_Obj01B_ProbStatBarrier "Probability of the object being a stationary road barrier";
CM_ SG_ 531 RFL_Obj01B_ProbStatObst "Probability of the object being a stationary obstacle";
CM_ SG_ 531 RFL_Obj01B_MovingProbability "Object has been observed moving over the ground";
CM_ SG_ 531 RFL_Obj01B_MovingObserved "Object has been observed moving over the ground since it was first detected";
CM_ SG_ 531 RFL_Obj01B_BehaviorType "Indicates that which behavior the object associated for";
CM_ SG_ 532 RFL_Obj02A_CRC "CRC - Autosar E2E Profile 5";
CM_ SG_ 532 RFL_Obj02A_Ay "Object relative acceleration in Y direction";
CM_ SG_ 532 RFL_Obj02A_HeadingYawAngle "Object heading yaw angle";
CM_ SG_ 532 RFL_Obj02A_Length "Object Length";
CM_ SG_ 532 RFL_Obj02A_Width "Object Width";
CM_ SG_ 532 RFL_Obj02A_Height "Object Height";
CM_ SG_ 532 RFL_Obj02A_DxVnce "Variance of object position in X direction";
CM_ SG_ 532 RFL_Obj02A_DyVnce "Variance of object position in Y direction";
CM_ SG_ 532 RFL_Obj02A_DzVnce "Variance of object position in Z direction";
CM_ SG_ 532 RFL_Obj02A_AliveCtr "Alive counter - Autosar E2E Profile 5";
CM_ SG_ 532 RFL_Obj02A_VxVnce "Variance of object relative velocity in X direction";
CM_ SG_ 532 RFL_Obj02A_VyVnce "Variance of object relative velocity in Y direction";
CM_ SG_ 532 RFL_Obj02A_AxVnce "Variance of object relative acceleration in X direction";
CM_ SG_ 532 RFL_Obj02A_AyVnce "Variance of object relative acceleration in Y direction";
CM_ SG_ 532 RFL_Obj02A_RefPosIndex "Reference Position of the detected objects";
CM_ SG_ 532 RFL_Obj02A_DxDyCoVnce "Covariance of Dx and Dy";
CM_ SG_ 532 RFL_Obj02A_DxVxCoVnce "Covariance of Dx and Vx";
CM_ SG_ 532 RFL_Obj02A_ProtBlockCtr "Protocol-Signal: Block-Counter";
CM_ SG_ 532 RFL_Obj02A_DyVxCoVnce "Covariance of Dy and Ax";
CM_ SG_ 532 RFL_Obj02A_DxVyCoVnce "Covariance of Dx and Vy";
CM_ SG_ 532 RFL_Obj02A_DyVyCoVnce "Covariance of Dy and Vy";
CM_ SG_ 532 RFL_Obj02A_VxVyCoVnce "Covariance of Vx and Vy";
CM_ SG_ 532 RFL_Obj02A_DxAxCoVnce "Covariance of Dx and Ax";
CM_ SG_ 532 RFL_Obj02A_DyAxCoVnce "Covariance of Dy and Ax";
CM_ SG_ 532 RFL_Obj02A_VxAxCoVnce "Covariance of Vx and Ax";
CM_ SG_ 532 RFL_Obj02A_ID "Unique Object ID";
CM_ SG_ 532 RFL_Obj02A_VyAxCoVnce "Covariance of Vy and Ax";
CM_ SG_ 532 RFL_Obj02A_DxAyCoVnce "Covariance of Dx and Ay";
CM_ SG_ 532 RFL_Obj02A_DyAyCoVnce "Covariance of Dy and Ay";
CM_ SG_ 532 RFL_Obj02A_VxAyCoVnce "Covariance of Vx and Ay";
CM_ SG_ 532 RFL_Obj02A_VyAyCoVnce "Covariance of Vy and Ay";
CM_ SG_ 532 RFL_Obj02A_AxAyCoVnce "Covariance of Ax and Ay";
CM_ SG_ 532 RFL_Obj02A_Measured "Object is measured or not";
CM_ SG_ 532 RFL_Obj02A_HeadingYawAngleVnce "Variance of object heading yaw angle";
CM_ SG_ 532 RFL_Obj02A_Dx "Object position in X direction";
CM_ SG_ 532 RFL_Obj02A_LengthVnce "Variance of object Length";
CM_ SG_ 532 RFL_Obj02A_WidthVnce "Variance of object Width";
CM_ SG_ 532 RFL_Obj02A_HeightVnce "Variance of object Height";
CM_ SG_ 532 RFL_Obj02A_ProbExist "Existence probability of object";
CM_ SG_ 532 RFL_Obj02A_ProbObstacle "Probability of the object being an Obstacle";
CM_ SG_ 532 RFL_Obj02A_ProbNonObstacle "Probability of the object being a Non-Obstacle";
CM_ SG_ 532 RFL_Obj02A_ProbMobileObst "Probability of the object being a mobile obstacle";
CM_ SG_ 532 RFL_Obj02A_Dz "Object position in Z direction";
CM_ SG_ 532 RFL_Obj02A_Dy "Object position in Y direction";
CM_ SG_ 532 RFL_Obj02A_Valid "Object is valid or not";
CM_ SG_ 532 RFL_Obj02A_Vx "Object relative velocity in X direction";
CM_ SG_ 532 RFL_Obj02A_Vy "Object relative velocity in Y direction";
CM_ SG_ 532 RFL_Obj02A_Ax "Object relative acceleration in X direction";
CM_ SG_ 533 RFL_Obj02B_CRC "CRC - Autosar E2E Profile 5";
CM_ SG_ 533 RFL_Obj02B_AliveCtr "Alive counter - Autosar E2E Profile 5";
CM_ SG_ 533 RFL_Obj02B_ProtBlockCtr "Protocol-Signal: Block-Counter";
CM_ SG_ 533 RFL_Obj02B_ProbMob4PlusWhl "Probability of a mobile object which has 4 or more wheels";
CM_ SG_ 533 RFL_Obj02B_ProbMob2Whl "Probability of a mobile object being 2-wheels vehicle";
CM_ SG_ 533 RFL_Obj02B_ProbMobPed "Probability of a mobile object being a pedestrian";
CM_ SG_ 533 RFL_Obj02B_Prob4PlusWhlCAR "Probability of a mobile object which has 4 or more wheels--passenger car";
CM_ SG_ 533 RFL_Obj02B_Prob4PlusWhlbHGV "Probability of a mobile object which has 4 or more wheels--commercial vehicle (Truck)";
CM_ SG_ 533 RFL_Obj02B_ProbGNDReflex "Probability of the object being a ground reflex";
CM_ SG_ 533 RFL_Obj02B_ProbStatBarrier "Probability of the object being a stationary road barrier";
CM_ SG_ 533 RFL_Obj02B_ProbStatObst "Probability of the object being a stationary obstacle";
CM_ SG_ 533 RFL_Obj02B_MovingProbability "Object has been observed moving over the ground";
CM_ SG_ 533 RFL_Obj02B_MovingObserved "Object has been observed moving over the ground since it was first detected";
CM_ SG_ 533 RFL_Obj02B_BehaviorType "Indicates that which behavior the object associated for";
CM_ SG_ 534 RFL_Obj03A_CRC "CRC - Autosar E2E Profile 5";
CM_ SG_ 534 RFL_Obj03A_Ay "Object relative acceleration in Y direction";
CM_ SG_ 534 RFL_Obj03A_HeadingYawAngle "Object heading yaw angle";
CM_ SG_ 534 RFL_Obj03A_Length "Object Length";
CM_ SG_ 534 RFL_Obj03A_Width "Object Width";
CM_ SG_ 534 RFL_Obj03A_Height "Object Height";
CM_ SG_ 534 RFL_Obj03A_DxVnce "Variance of object position in X direction";
CM_ SG_ 534 RFL_Obj03A_DyVnce "Variance of object position in Y direction";
CM_ SG_ 534 RFL_Obj03A_DzVnce "Variance of object position in Z direction";
CM_ SG_ 534 RFL_Obj03A_AliveCtr "Alive counter - Autosar E2E Profile 5";
CM_ SG_ 534 RFL_Obj03A_VxVnce "Variance of object relative velocity in X direction";
CM_ SG_ 534 RFL_Obj03A_VyVnce "Variance of object relative velocity in Y direction";
CM_ SG_ 534 RFL_Obj03A_AxVnce "Variance of object relative acceleration in X direction";
CM_ SG_ 534 RFL_Obj03A_AyVnce "Variance of object relative acceleration in Y direction";
CM_ SG_ 534 RFL_Obj03A_RefPosIndex "Reference Position of the detected objects";
CM_ SG_ 534 RFL_Obj03A_DxDyCoVnce "Covariance of Dx and Dy";
CM_ SG_ 534 RFL_Obj03A_DxVxCoVnce "Covariance of Dx and Vx";
CM_ SG_ 534 RFL_Obj03A_ProtBlockCtr "Protocol-Signal: Block-Counter";
CM_ SG_ 534 RFL_Obj03A_DyVxCoVnce "Covariance of Dy and Ax";
CM_ SG_ 534 RFL_Obj03A_DxVyCoVnce "Covariance of Dx and Vy";
CM_ SG_ 534 RFL_Obj03A_DyVyCoVnce "Covariance of Dy and Vy";
CM_ SG_ 534 RFL_Obj03A_VxVyCoVnce "Covariance of Vx and Vy";
CM_ SG_ 534 RFL_Obj03A_DxAxCoVnce "Covariance of Dx and Ax";
CM_ SG_ 534 RFL_Obj03A_DyAxCoVnce "Covariance of Dy and Ax";
CM_ SG_ 534 RFL_Obj03A_VxAxCoVnce "Covariance of Vx and Ax";
CM_ SG_ 534 RFL_Obj03A_ID "Unique Object ID";
CM_ SG_ 534 RFL_Obj03A_VyAxCoVnce "Covariance of Vy and Ax";
CM_ SG_ 534 RFL_Obj03A_DxAyCoVnce "Covariance of Dx and Ay";
CM_ SG_ 534 RFL_Obj03A_DyAyCoVnce "Covariance of Dy and Ay";
CM_ SG_ 534 RFL_Obj03A_VxAyCoVnce "Covariance of Vx and Ay";
CM_ SG_ 534 RFL_Obj03A_VyAyCoVnce "Covariance of Vy and Ay";
CM_ SG_ 534 RFL_Obj03A_AxAyCoVnce "Covariance of Ax and Ay";
CM_ SG_ 534 RFL_Obj03A_Measured "Object is measured or not";
CM_ SG_ 534 RFL_Obj03A_HeadingYawAngleVnce "Variance of object heading yaw angle";
CM_ SG_ 534 RFL_Obj03A_Dx "Object position in X direction";
CM_ SG_ 534 RFL_Obj03A_LengthVnce "Variance of object Length";
CM_ SG_ 534 RFL_Obj03A_WidthVnce "Variance of object Width";
CM_ SG_ 534 RFL_Obj03A_HeightVnce "Variance of object Height";
CM_ SG_ 534 RFL_Obj03A_ProbExist "Existence probability of object";
CM_ SG_ 534 RFL_Obj03A_ProbObstacle "Probability of the object being an Obstacle";
CM_ SG_ 534 RFL_Obj03A_ProbNonObstacle "Probability of the object being a Non-Obstacle";
CM_ SG_ 534 RFL_Obj03A_ProbMobileObst "Probability of the object being a mobile obstacle";
CM_ SG_ 534 RFL_Obj03A_Dz "Object position in Z direction";
CM_ SG_ 534 RFL_Obj03A_Dy "Object position in Y direction";
CM_ SG_ 534 RFL_Obj03A_Valid "Object is valid or not";
CM_ SG_ 534 RFL_Obj03A_Vx "Object relative velocity in X direction";
CM_ SG_ 534 RFL_Obj03A_Vy "Object relative velocity in Y direction";
CM_ SG_ 534 RFL_Obj03A_Ax "Object relative acceleration in X direction";
CM_ SG_ 535 RFL_Obj03B_CRC "CRC - Autosar E2E Profile 5";
CM_ SG_ 535 RFL_Obj03B_AliveCtr "Alive counter - Autosar E2E Profile 5";
CM_ SG_ 535 RFL_Obj03B_ProtBlockCtr "Protocol-Signal: Block-Counter";
CM_ SG_ 535 RFL_Obj03B_ProbMob4PlusWhl "Probability of a mobile object which has 4 or more wheels";
CM_ SG_ 535 RFL_Obj03B_ProbMob2Whl "Probability of a mobile object being 2-wheels vehicle";
CM_ SG_ 535 RFL_Obj03B_ProbMobPed "Probability of a mobile object being a pedestrian";
CM_ SG_ 535 RFL_Obj03B_Prob4PlusWhlCAR "Probability of a mobile object which has 4 or more wheels--passenger car";
CM_ SG_ 535 RFL_Obj03B_Prob4PlusWhlbHGV "Probability of a mobile object which has 4 or more wheels--commercial vehicle (Truck)";
CM_ SG_ 535 RFL_Obj03B_ProbGNDReflex "Probability of the object being a ground reflex";
CM_ SG_ 535 RFL_Obj03B_ProbStatBarrier "Probability of the object being a stationary road barrier";
CM_ SG_ 535 RFL_Obj03B_ProbStatObst "Probability of the object being a stationary obstacle";
CM_ SG_ 535 RFL_Obj03B_MovingProbability "Object has been observed moving over the ground";
CM_ SG_ 535 RFL_Obj03B_MovingObserved "Object has been observed moving over the ground since it was first detected";
CM_ SG_ 535 RFL_Obj03B_BehaviorType "Indicates that which behavior the object associated for";
CM_ SG_ 536 RFL_Obj04A_CRC "CRC - Autosar E2E Profile 5";
CM_ SG_ 536 RFL_Obj04A_Ay "Object relative acceleration in Y direction";
CM_ SG_ 536 RFL_Obj04A_HeadingYawAngle "Object heading yaw angle";
CM_ SG_ 536 RFL_Obj04A_Length "Object Length";
CM_ SG_ 536 RFL_Obj04A_Width "Object Width";
CM_ SG_ 536 RFL_Obj04A_Height "Object Height";
CM_ SG_ 536 RFL_Obj04A_DxVnce "Variance of object position in X direction";
CM_ SG_ 536 RFL_Obj04A_DyVnce "Variance of object position in Y direction";
CM_ SG_ 536 RFL_Obj04A_DzVnce "Variance of object position in Z direction";
CM_ SG_ 536 RFL_Obj04A_AliveCtr "Alive counter - Autosar E2E Profile 5";
CM_ SG_ 536 RFL_Obj04A_VxVnce "Variance of object relative velocity in X direction";
CM_ SG_ 536 RFL_Obj04A_VyVnce "Variance of object relative velocity in Y direction";
CM_ SG_ 536 RFL_Obj04A_AxVnce "Variance of object relative acceleration in X direction";
CM_ SG_ 536 RFL_Obj04A_AyVnce "Variance of object relative acceleration in Y direction";
CM_ SG_ 536 RFL_Obj04A_RefPosIndex "Reference Position of the detected objects";
CM_ SG_ 536 RFL_Obj04A_DxDyCoVnce "Covariance of Dx and Dy";
CM_ SG_ 536 RFL_Obj04A_DxVxCoVnce "Covariance of Dx and Vx";
CM_ SG_ 536 RFL_Obj04A_ProtBlockCtr "Protocol-Signal: Block-Counter";
CM_ SG_ 536 RFL_Obj04A_DyVxCoVnce "Covariance of Dy and Ax";
CM_ SG_ 536 RFL_Obj04A_DxVyCoVnce "Covariance of Dx and Vy";
CM_ SG_ 536 RFL_Obj04A_DyVyCoVnce "Covariance of Dy and Vy";
CM_ SG_ 536 RFL_Obj04A_VxVyCoVnce "Covariance of Vx and Vy";
CM_ SG_ 536 RFL_Obj04A_DxAxCoVnce "Covariance of Dx and Ax";
CM_ SG_ 536 RFL_Obj04A_DyAxCoVnce "Covariance of Dy and Ax";
CM_ SG_ 536 RFL_Obj04A_VxAxCoVnce "Covariance of Vx and Ax";
CM_ SG_ 536 RFL_Obj04A_ID "Unique Object ID";
CM_ SG_ 536 RFL_Obj04A_VyAxCoVnce "Covariance of Vy and Ax";
CM_ SG_ 536 RFL_Obj04A_DxAyCoVnce "Covariance of Dx and Ay";
CM_ SG_ 536 RFL_Obj04A_DyAyCoVnce "Covariance of Dy and Ay";
CM_ SG_ 536 RFL_Obj04A_VxAyCoVnce "Covariance of Vx and Ay";
CM_ SG_ 536 RFL_Obj04A_VyAyCoVnce "Covariance of Vy and Ay";
CM_ SG_ 536 RFL_Obj04A_AxAyCoVnce "Covariance of Ax and Ay";
CM_ SG_ 536 RFL_Obj04A_Measured "Object is measured or not";
CM_ SG_ 536 RFL_Obj04A_HeadingYawAngleVnce "Variance of object heading yaw angle";
CM_ SG_ 536 RFL_Obj04A_Dx "Object position in X direction";
CM_ SG_ 536 RFL_Obj04A_LengthVnce "Variance of object Length";
CM_ SG_ 536 RFL_Obj04A_WidthVnce "Variance of object Width";
CM_ SG_ 536 RFL_Obj04A_HeightVnce "Variance of object Height";
CM_ SG_ 536 RFL_Obj04A_ProbExist "Existence probability of object";
CM_ SG_ 536 RFL_Obj04A_ProbObstacle "Probability of the object being an Obstacle";
CM_ SG_ 536 RFL_Obj04A_ProbNonObstacle "Probability of the object being a Non-Obstacle";
CM_ SG_ 536 RFL_Obj04A_ProbMobileObst "Probability of the object being a mobile obstacle";
CM_ SG_ 536 RFL_Obj04A_Dz "Object position in Z direction";
CM_ SG_ 536 RFL_Obj04A_Dy "Object position in Y direction";
CM_ SG_ 536 RFL_Obj04A_Valid "Object is valid or not";
CM_ SG_ 536 RFL_Obj04A_Vx "Object relative velocity in X direction";
CM_ SG_ 536 RFL_Obj04A_Vy "Object relative velocity in Y direction";
CM_ SG_ 536 RFL_Obj04A_Ax "Object relative acceleration in X direction";
CM_ SG_ 537 RFL_Obj04B_CRC "CRC - Autosar E2E Profile 5";
CM_ SG_ 537 RFL_Obj04B_AliveCtr "Alive counter - Autosar E2E Profile 5";
CM_ SG_ 537 RFL_Obj04B_ProtBlockCtr "Protocol-Signal: Block-Counter";
CM_ SG_ 537 RFL_Obj04B_ProbMob4PlusWhl "Probability of a mobile object which has 4 or more wheels";
CM_ SG_ 537 RFL_Obj04B_ProbMob2Whl "Probability of a mobile object being 2-wheels vehicle";
CM_ SG_ 537 RFL_Obj04B_ProbMobPed "Probability of a mobile object being a pedestrian";
CM_ SG_ 537 RFL_Obj04B_Prob4PlusWhlCAR "Probability of a mobile object which has 4 or more wheels--passenger car";
CM_ SG_ 537 RFL_Obj04B_Prob4PlusWhlbHGV "Probability of a mobile object which has 4 or more wheels--commercial vehicle (Truck)";
CM_ SG_ 537 RFL_Obj04B_ProbGNDReflex "Probability of the object being a ground reflex";
CM_ SG_ 537 RFL_Obj04B_ProbStatBarrier "Probability of the object being a stationary road barrier";
CM_ SG_ 537 RFL_Obj04B_ProbStatObst "Probability of the object being a stationary obstacle";
CM_ SG_ 537 RFL_Obj04B_MovingProbability "Object has been observed moving over the ground";
CM_ SG_ 537 RFL_Obj04B_MovingObserved "Object has been observed moving over the ground since it was first detected";
CM_ SG_ 537 RFL_Obj04B_BehaviorType "Indicates that which behavior the object associated for";
CM_ SG_ 538 RFL_Obj05A_CRC "CRC - Autosar E2E Profile 5";
CM_ SG_ 538 RFL_Obj05A_Ay "Object relative acceleration in Y direction";
CM_ SG_ 538 RFL_Obj05A_HeadingYawAngle "Object heading yaw angle";
CM_ SG_ 538 RFL_Obj05A_Length "Object Length";
CM_ SG_ 538 RFL_Obj05A_Width "Object Width";
CM_ SG_ 538 RFL_Obj05A_Height "Object Height";
CM_ SG_ 538 RFL_Obj05A_DxVnce "Variance of object position in X direction";
CM_ SG_ 538 RFL_Obj05A_DyVnce "Variance of object position in Y direction";
CM_ SG_ 538 RFL_Obj05A_DzVnce "Variance of object position in Z direction";
CM_ SG_ 538 RFL_Obj05A_AliveCtr "Alive counter - Autosar E2E Profile 5";
CM_ SG_ 538 RFL_Obj05A_VxVnce "Variance of object relative velocity in X direction";
CM_ SG_ 538 RFL_Obj05A_VyVnce "Variance of object relative velocity in Y direction";
CM_ SG_ 538 RFL_Obj05A_AxVnce "Variance of object relative acceleration in X direction";
CM_ SG_ 538 RFL_Obj05A_AyVnce "Variance of object relative acceleration in Y direction";
CM_ SG_ 538 RFL_Obj05A_RefPosIndex "Reference Position of the detected objects";
CM_ SG_ 538 RFL_Obj05A_DxDyCoVnce "Covariance of Dx and Dy";
CM_ SG_ 538 RFL_Obj05A_DxVxCoVnce "Covariance of Dx and Vx";
CM_ SG_ 538 RFL_Obj05A_ProtBlockCtr "Protocol-Signal: Block-Counter";
CM_ SG_ 538 RFL_Obj05A_DyVxCoVnce "Covariance of Dy and Ax";
CM_ SG_ 538 RFL_Obj05A_DxVyCoVnce "Covariance of Dx and Vy";
CM_ SG_ 538 RFL_Obj05A_DyVyCoVnce "Covariance of Dy and Vy";
CM_ SG_ 538 RFL_Obj05A_VxVyCoVnce "Covariance of Vx and Vy";
CM_ SG_ 538 RFL_Obj05A_DxAxCoVnce "Covariance of Dx and Ax";
CM_ SG_ 538 RFL_Obj05A_DyAxCoVnce "Covariance of Dy and Ax";
CM_ SG_ 538 RFL_Obj05A_VxAxCoVnce "Covariance of Vx and Ax";
CM_ SG_ 538 RFL_Obj05A_ID "Unique Object ID";
CM_ SG_ 538 RFL_Obj05A_VyAxCoVnce "Covariance of Vy and Ax";
CM_ SG_ 538 RFL_Obj05A_DxAyCoVnce "Covariance of Dx and Ay";
CM_ SG_ 538 RFL_Obj05A_DyAyCoVnce "Covariance of Dy and Ay";
CM_ SG_ 538 RFL_Obj05A_VxAyCoVnce "Covariance of Vx and Ay";
CM_ SG_ 538 RFL_Obj05A_VyAyCoVnce "Covariance of Vy and Ay";
CM_ SG_ 538 RFL_Obj05A_AxAyCoVnce "Covariance of Ax and Ay";
CM_ SG_ 538 RFL_Obj05A_Measured "Object is measured or not";
CM_ SG_ 538 RFL_Obj05A_HeadingYawAngleVnce "Variance of object heading yaw angle";
CM_ SG_ 538 RFL_Obj05A_Dx "Object position in X direction";
CM_ SG_ 538 RFL_Obj05A_LengthVnce "Variance of object Length";
CM_ SG_ 538 RFL_Obj05A_WidthVnce "Variance of object Width";
CM_ SG_ 538 RFL_Obj05A_HeightVnce "Variance of object Height";
CM_ SG_ 538 RFL_Obj05A_ProbExist "Existence probability of object";
CM_ SG_ 538 RFL_Obj05A_ProbObstacle "Probability of the object being an Obstacle";
CM_ SG_ 538 RFL_Obj05A_ProbNonObstacle "Probability of the object being a Non-Obstacle";
CM_ SG_ 538 RFL_Obj05A_ProbMobileObst "Probability of the object being a mobile obstacle";
CM_ SG_ 538 RFL_Obj05A_Dz "Object position in Z direction";
CM_ SG_ 538 RFL_Obj05A_Dy "Object position in Y direction";
CM_ SG_ 538 RFL_Obj05A_Valid "Object is valid or not";
CM_ SG_ 538 RFL_Obj05A_Vx "Object relative velocity in X direction";
CM_ SG_ 538 RFL_Obj05A_Vy "Object relative velocity in Y direction";
CM_ SG_ 538 RFL_Obj05A_Ax "Object relative acceleration in X direction";
CM_ SG_ 539 RFL_Obj05B_CRC "CRC - Autosar E2E Profile 5";
CM_ SG_ 539 RFL_Obj05B_AliveCtr "Alive counter - Autosar E2E Profile 5";
CM_ SG_ 539 RFL_Obj05B_ProtBlockCtr "Protocol-Signal: Block-Counter";
CM_ SG_ 539 RFL_Obj05B_ProbMob4PlusWhl "Probability of a mobile object which has 4 or more wheels";
CM_ SG_ 539 RFL_Obj05B_ProbMob2Whl "Probability of a mobile object being 2-wheels vehicle";
CM_ SG_ 539 RFL_Obj05B_ProbMobPed "Probability of a mobile object being a pedestrian";
CM_ SG_ 539 RFL_Obj05B_Prob4PlusWhlCAR "Probability of a mobile object which has 4 or more wheels--passenger car";
CM_ SG_ 539 RFL_Obj05B_Prob4PlusWhlbHGV "Probability of a mobile object which has 4 or more wheels--commercial vehicle (Truck)";
CM_ SG_ 539 RFL_Obj05B_ProbGNDReflex "Probability of the object being a ground reflex";
CM_ SG_ 539 RFL_Obj05B_ProbStatBarrier "Probability of the object being a stationary road barrier";
CM_ SG_ 539 RFL_Obj05B_ProbStatObst "Probability of the object being a stationary obstacle";
CM_ SG_ 539 RFL_Obj05B_MovingProbability "Object has been observed moving over the ground";
CM_ SG_ 539 RFL_Obj05B_MovingObserved "Object has been observed moving over the ground since it was first detected";
CM_ SG_ 539 RFL_Obj05B_BehaviorType "Indicates that which behavior the object associated for";
CM_ SG_ 540 RFL_Obj06A_CRC "CRC - Autosar E2E Profile 5";
CM_ SG_ 540 RFL_Obj06A_Ay "Object relative acceleration in Y direction";
CM_ SG_ 540 RFL_Obj06A_HeadingYawAngle "Object heading yaw angle";
CM_ SG_ 540 RFL_Obj06A_Length "Object Length";
CM_ SG_ 540 RFL_Obj06A_Width "Object Width";
CM_ SG_ 540 RFL_Obj06A_Height "Object Height";
CM_ SG_ 540 RFL_Obj06A_DxVnce "Variance of object position in X direction";
CM_ SG_ 540 RFL_Obj06A_DyVnce "Variance of object position in Y direction";
CM_ SG_ 540 RFL_Obj06A_DzVnce "Variance of object position in Z direction";
CM_ SG_ 540 RFL_Obj06A_AliveCtr "Alive counter - Autosar E2E Profile 5";
CM_ SG_ 540 RFL_Obj06A_VxVnce "Variance of object relative velocity in X direction";
CM_ SG_ 540 RFL_Obj06A_VyVnce "Variance of object relative velocity in Y direction";
CM_ SG_ 540 RFL_Obj06A_AxVnce "Variance of object relative acceleration in X direction";
CM_ SG_ 540 RFL_Obj06A_AyVnce "Variance of object relative acceleration in Y direction";
CM_ SG_ 540 RFL_Obj06A_RefPosIndex "Reference Position of the detected objects";
CM_ SG_ 540 RFL_Obj06A_DxDyCoVnce "Covariance of Dx and Dy";
CM_ SG_ 540 RFL_Obj06A_DxVxCoVnce "Covariance of Dx and Vx";
CM_ SG_ 540 RFL_Obj06A_ProtBlockCtr "Protocol-Signal: Block-Counter";
CM_ SG_ 540 RFL_Obj06A_DyVxCoVnce "Covariance of Dy and Ax";
CM_ SG_ 540 RFL_Obj06A_DxVyCoVnce "Covariance of Dx and Vy";
CM_ SG_ 540 RFL_Obj06A_DyVyCoVnce "Covariance of Dy and Vy";
CM_ SG_ 540 RFL_Obj06A_VxVyCoVnce "Covariance of Vx and Vy";
CM_ SG_ 540 RFL_Obj06A_DxAxCoVnce "Covariance of Dx and Ax";
CM_ SG_ 540 RFL_Obj06A_DyAxCoVnce "Covariance of Dy and Ax";
CM_ SG_ 540 RFL_Obj06A_VxAxCoVnce "Covariance of Vx and Ax";
CM_ SG_ 540 RFL_Obj06A_ID "Unique Object ID";
CM_ SG_ 540 RFL_Obj06A_VyAxCoVnce "Covariance of Vy and Ax";
CM_ SG_ 540 RFL_Obj06A_DxAyCoVnce "Covariance of Dx and Ay";
CM_ SG_ 540 RFL_Obj06A_DyAyCoVnce "Covariance of Dy and Ay";
CM_ SG_ 540 RFL_Obj06A_VxAyCoVnce "Covariance of Vx and Ay";
CM_ SG_ 540 RFL_Obj06A_VyAyCoVnce "Covariance of Vy and Ay";
CM_ SG_ 540 RFL_Obj06A_AxAyCoVnce "Covariance of Ax and Ay";
CM_ SG_ 540 RFL_Obj06A_Measured "Object is measured or not";
CM_ SG_ 540 RFL_Obj06A_HeadingYawAngleVnce "Variance of object heading yaw angle";
CM_ SG_ 540 RFL_Obj06A_Dx "Object position in X direction";
CM_ SG_ 540 RFL_Obj06A_LengthVnce "Variance of object Length";
CM_ SG_ 540 RFL_Obj06A_WidthVnce "Variance of object Width";
CM_ SG_ 540 RFL_Obj06A_HeightVnce "Variance of object Height";
CM_ SG_ 540 RFL_Obj06A_ProbExist "Existence probability of object";
CM_ SG_ 540 RFL_Obj06A_ProbObstacle "Probability of the object being an Obstacle";
CM_ SG_ 540 RFL_Obj06A_ProbNonObstacle "Probability of the object being a Non-Obstacle";
CM_ SG_ 540 RFL_Obj06A_ProbMobileObst "Probability of the object being a mobile obstacle";
CM_ SG_ 540 RFL_Obj06A_Dz "Object position in Z direction";
CM_ SG_ 540 RFL_Obj06A_Dy "Object position in Y direction";
CM_ SG_ 540 RFL_Obj06A_Valid "Object is valid or not";
CM_ SG_ 540 RFL_Obj06A_Vx "Object relative velocity in X direction";
CM_ SG_ 540 RFL_Obj06A_Vy "Object relative velocity in Y direction";
CM_ SG_ 540 RFL_Obj06A_Ax "Object relative acceleration in X direction";
CM_ SG_ 541 RFL_Obj06B_CRC "CRC - Autosar E2E Profile 5";
CM_ SG_ 541 RFL_Obj06B_AliveCtr "Alive counter - Autosar E2E Profile 5";
CM_ SG_ 541 RFL_Obj06B_ProtBlockCtr "Protocol-Signal: Block-Counter";
CM_ SG_ 541 RFL_Obj06B_ProbMob4PlusWhl "Probability of a mobile object which has 4 or more wheels";
CM_ SG_ 541 RFL_Obj06B_ProbMob2Whl "Probability of a mobile object being 2-wheels vehicle";
CM_ SG_ 541 RFL_Obj06B_ProbMobPed "Probability of a mobile object being a pedestrian";
CM_ SG_ 541 RFL_Obj06B_Prob4PlusWhlCAR "Probability of a mobile object which has 4 or more wheels--passenger car";
CM_ SG_ 541 RFL_Obj06B_Prob4PlusWhlbHGV "Probability of a mobile object which has 4 or more wheels--commercial vehicle (Truck)";
CM_ SG_ 541 RFL_Obj06B_ProbGNDReflex "Probability of the object being a ground reflex";
CM_ SG_ 541 RFL_Obj06B_ProbStatBarrier "Probability of the object being a stationary road barrier";
CM_ SG_ 541 RFL_Obj06B_ProbStatObst "Probability of the object being a stationary obstacle";
CM_ SG_ 541 RFL_Obj06B_MovingProbability "Object has been observed moving over the ground";
CM_ SG_ 541 RFL_Obj06B_MovingObserved "Object has been observed moving over the ground since it was first detected";
CM_ SG_ 541 RFL_Obj06B_BehaviorType "Indicates that which behavior the object associated for";
CM_ SG_ 542 RFL_Obj07A_CRC "CRC - Autosar E2E Profile 5";
CM_ SG_ 542 RFL_Obj07A_Ay "Object relative acceleration in Y direction";
CM_ SG_ 542 RFL_Obj07A_HeadingYawAngle "Object heading yaw angle";
CM_ SG_ 542 RFL_Obj07A_Length "Object Length";
CM_ SG_ 542 RFL_Obj07A_Width "Object Width";
CM_ SG_ 542 RFL_Obj07A_Height "Object Height";
CM_ SG_ 542 RFL_Obj07A_DxVnce "Variance of object position in X direction";
CM_ SG_ 542 RFL_Obj07A_DyVnce "Variance of object position in Y direction";
CM_ SG_ 542 RFL_Obj07A_DzVnce "Variance of object position in Z direction";
CM_ SG_ 542 RFL_Obj07A_AliveCtr "Alive counter - Autosar E2E Profile 5";
CM_ SG_ 542 RFL_Obj07A_VxVnce "Variance of object relative velocity in X direction";
CM_ SG_ 542 RFL_Obj07A_VyVnce "Variance of object relative velocity in Y direction";
CM_ SG_ 542 RFL_Obj07A_AxVnce "Variance of object relative acceleration in X direction";
CM_ SG_ 542 RFL_Obj07A_AyVnce "Variance of object relative acceleration in Y direction";
CM_ SG_ 542 RFL_Obj07A_RefPosIndex "Reference Position of the detected objects";
CM_ SG_ 542 RFL_Obj07A_DxDyCoVnce "Covariance of Dx and Dy";
CM_ SG_ 542 RFL_Obj07A_DxVxCoVnce "Covariance of Dx and Vx";
CM_ SG_ 542 RFL_Obj07A_ProtBlockCtr "Protocol-Signal: Block-Counter";
CM_ SG_ 542 RFL_Obj07A_DyVxCoVnce "Covariance of Dy and Ax";
CM_ SG_ 542 RFL_Obj07A_DxVyCoVnce "Covariance of Dx and Vy";
CM_ SG_ 542 RFL_Obj07A_DyVyCoVnce "Covariance of Dy and Vy";
CM_ SG_ 542 RFL_Obj07A_VxVyCoVnce "Covariance of Vx and Vy";
CM_ SG_ 542 RFL_Obj07A_DxAxCoVnce "Covariance of Dx and Ax";
CM_ SG_ 542 RFL_Obj07A_DyAxCoVnce "Covariance of Dy and Ax";
CM_ SG_ 542 RFL_Obj07A_VxAxCoVnce "Covariance of Vx and Ax";
CM_ SG_ 542 RFL_Obj07A_ID "Unique Object ID";
CM_ SG_ 542 RFL_Obj07A_VyAxCoVnce "Covariance of Vy and Ax";
CM_ SG_ 542 RFL_Obj07A_DxAyCoVnce "Covariance of Dx and Ay";
CM_ SG_ 542 RFL_Obj07A_DyAyCoVnce "Covariance of Dy and Ay";
CM_ SG_ 542 RFL_Obj07A_VxAyCoVnce "Covariance of Vx and Ay";
CM_ SG_ 542 RFL_Obj07A_VyAyCoVnce "Covariance of Vy and Ay";
CM_ SG_ 542 RFL_Obj07A_AxAyCoVnce "Covariance of Ax and Ay";
CM_ SG_ 542 RFL_Obj07A_Measured "Object is measured or not";
CM_ SG_ 542 RFL_Obj07A_HeadingYawAngleVnce "Variance of object heading yaw angle";
CM_ SG_ 542 RFL_Obj07A_Dx "Object position in X direction";
CM_ SG_ 542 RFL_Obj07A_LengthVnce "Variance of object Length";
CM_ SG_ 542 RFL_Obj07A_WidthVnce "Variance of object Width";
CM_ SG_ 542 RFL_Obj07A_HeightVnce "Variance of object Height";
CM_ SG_ 542 RFL_Obj07A_ProbExist "Existence probability of object";
CM_ SG_ 542 RFL_Obj07A_ProbObstacle "Probability of the object being an Obstacle";
CM_ SG_ 542 RFL_Obj07A_ProbNonObstacle "Probability of the object being a Non-Obstacle";
CM_ SG_ 542 RFL_Obj07A_ProbMobileObst "Probability of the object being a mobile obstacle";
CM_ SG_ 542 RFL_Obj07A_Dz "Object position in Z direction";
CM_ SG_ 542 RFL_Obj07A_Dy "Object position in Y direction";
CM_ SG_ 542 RFL_Obj07A_Valid "Object is valid or not";
CM_ SG_ 542 RFL_Obj07A_Vx "Object relative velocity in X direction";
CM_ SG_ 542 RFL_Obj07A_Vy "Object relative velocity in Y direction";
CM_ SG_ 542 RFL_Obj07A_Ax "Object relative acceleration in X direction";
CM_ SG_ 543 RFL_Obj07B_CRC "CRC - Autosar E2E Profile 5";
CM_ SG_ 543 RFL_Obj07B_AliveCtr "Alive counter - Autosar E2E Profile 5";
CM_ SG_ 543 RFL_Obj07B_ProtBlockCtr "Protocol-Signal: Block-Counter";
CM_ SG_ 543 RFL_Obj07B_ProbMob4PlusWhl "Probability of a mobile object which has 4 or more wheels";
CM_ SG_ 543 RFL_Obj07B_ProbMob2Whl "Probability of a mobile object being 2-wheels vehicle";
CM_ SG_ 543 RFL_Obj07B_ProbMobPed "Probability of a mobile object being a pedestrian";
CM_ SG_ 543 RFL_Obj07B_Prob4PlusWhlCAR "Probability of a mobile object which has 4 or more wheels--passenger car";
CM_ SG_ 543 RFL_Obj07B_Prob4PlusWhlbHGV "Probability of a mobile object which has 4 or more wheels--commercial vehicle (Truck)";
CM_ SG_ 543 RFL_Obj07B_ProbGNDReflex "Probability of the object being a ground reflex";
CM_ SG_ 543 RFL_Obj07B_ProbStatBarrier "Probability of the object being a stationary road barrier";
CM_ SG_ 543 RFL_Obj07B_ProbStatObst "Probability of the object being a stationary obstacle";
CM_ SG_ 543 RFL_Obj07B_MovingProbability "Object has been observed moving over the ground";
CM_ SG_ 543 RFL_Obj07B_MovingObserved "Object has been observed moving over the ground since it was first detected";
CM_ SG_ 543 RFL_Obj07B_BehaviorType "Indicates that which behavior the object associated for";
CM_ SG_ 544 RFL_Obj08A_CRC "CRC - Autosar E2E Profile 5";
CM_ SG_ 544 RFL_Obj08A_Ay "Object relative acceleration in Y direction";
CM_ SG_ 544 RFL_Obj08A_HeadingYawAngle "Object heading yaw angle";
CM_ SG_ 544 RFL_Obj08A_Length "Object Length";
CM_ SG_ 544 RFL_Obj08A_Width "Object Width";
CM_ SG_ 544 RFL_Obj08A_Height "Object Height";
CM_ SG_ 544 RFL_Obj08A_DxVnce "Variance of object position in X direction";
CM_ SG_ 544 RFL_Obj08A_DyVnce "Variance of object position in Y direction";
CM_ SG_ 544 RFL_Obj08A_DzVnce "Variance of object position in Z direction";
CM_ SG_ 544 RFL_Obj08A_AliveCtr "Alive counter - Autosar E2E Profile 5";
CM_ SG_ 544 RFL_Obj08A_VxVnce "Variance of object relative velocity in X direction";
CM_ SG_ 544 RFL_Obj08A_VyVnce "Variance of object relative velocity in Y direction";
CM_ SG_ 544 RFL_Obj08A_AxVnce "Variance of object relative acceleration in X direction";
CM_ SG_ 544 RFL_Obj08A_AyVnce "Variance of object relative acceleration in Y direction";
CM_ SG_ 544 RFL_Obj08A_RefPosIndex "Reference Position of the detected objects";
CM_ SG_ 544 RFL_Obj08A_DxDyCoVnce "Covariance of Dx and Dy";
CM_ SG_ 544 RFL_Obj08A_DxVxCoVnce "Covariance of Dx and Vx";
CM_ SG_ 544 RFL_Obj08A_ProtBlockCtr "Protocol-Signal: Block-Counter";
CM_ SG_ 544 RFL_Obj08A_DyVxCoVnce "Covariance of Dy and Ax";
CM_ SG_ 544 RFL_Obj08A_DxVyCoVnce "Covariance of Dx and Vy";
CM_ SG_ 544 RFL_Obj08A_DyVyCoVnce "Covariance of Dy and Vy";
CM_ SG_ 544 RFL_Obj08A_VxVyCoVnce "Covariance of Vx and Vy";
CM_ SG_ 544 RFL_Obj08A_DxAxCoVnce "Covariance of Dx and Ax";
CM_ SG_ 544 RFL_Obj08A_DyAxCoVnce "Covariance of Dy and Ax";
CM_ SG_ 544 RFL_Obj08A_VxAxCoVnce "Covariance of Vx and Ax";
CM_ SG_ 544 RFL_Obj08A_ID "Unique Object ID";
CM_ SG_ 544 RFL_Obj08A_VyAxCoVnce "Covariance of Vy and Ax";
CM_ SG_ 544 RFL_Obj08A_DxAyCoVnce "Covariance of Dx and Ay";
CM_ SG_ 544 RFL_Obj08A_DyAyCoVnce "Covariance of Dy and Ay";
CM_ SG_ 544 RFL_Obj08A_VxAyCoVnce "Covariance of Vx and Ay";
CM_ SG_ 544 RFL_Obj08A_VyAyCoVnce "Covariance of Vy and Ay";
CM_ SG_ 544 RFL_Obj08A_AxAyCoVnce "Covariance of Ax and Ay";
CM_ SG_ 544 RFL_Obj08A_Measured "Object is measured or not";
CM_ SG_ 544 RFL_Obj08A_HeadingYawAngleVnce "Variance of object heading yaw angle";
CM_ SG_ 544 RFL_Obj08A_Dx "Object position in X direction";
CM_ SG_ 544 RFL_Obj08A_LengthVnce "Variance of object Length";
CM_ SG_ 544 RFL_Obj08A_WidthVnce "Variance of object Width";
CM_ SG_ 544 RFL_Obj08A_HeightVnce "Variance of object Height";
CM_ SG_ 544 RFL_Obj08A_ProbExist "Existence probability of object";
CM_ SG_ 544 RFL_Obj08A_ProbObstacle "Probability of the object being an Obstacle";
CM_ SG_ 544 RFL_Obj08A_ProbNonObstacle "Probability of the object being a Non-Obstacle";
CM_ SG_ 544 RFL_Obj08A_ProbMobileObst "Probability of the object being a mobile obstacle";
CM_ SG_ 544 RFL_Obj08A_Dz "Object position in Z direction";
CM_ SG_ 544 RFL_Obj08A_Dy "Object position in Y direction";
CM_ SG_ 544 RFL_Obj08A_Valid "Object is valid or not";
CM_ SG_ 544 RFL_Obj08A_Vx "Object relative velocity in X direction";
CM_ SG_ 544 RFL_Obj08A_Vy "Object relative velocity in Y direction";
CM_ SG_ 544 RFL_Obj08A_Ax "Object relative acceleration in X direction";
CM_ SG_ 545 RFL_Obj08B_CRC "CRC - Autosar E2E Profile 5";
CM_ SG_ 545 RFL_Obj08B_AliveCtr "Alive counter - Autosar E2E Profile 5";
CM_ SG_ 545 RFL_Obj08B_ProtBlockCtr "Protocol-Signal: Block-Counter";
CM_ SG_ 545 RFL_Obj08B_ProbMob4PlusWhl "Probability of a mobile object which has 4 or more wheels";
CM_ SG_ 545 RFL_Obj08B_ProbMob2Whl "Probability of a mobile object being 2-wheels vehicle";
CM_ SG_ 545 RFL_Obj08B_ProbMobPed "Probability of a mobile object being a pedestrian";
CM_ SG_ 545 RFL_Obj08B_Prob4PlusWhlCAR "Probability of a mobile object which has 4 or more wheels--passenger car";
CM_ SG_ 545 RFL_Obj08B_Prob4PlusWhlbHGV "Probability of a mobile object which has 4 or more wheels--commercial vehicle (Truck)";
CM_ SG_ 545 RFL_Obj08B_ProbGNDReflex "Probability of the object being a ground reflex";
CM_ SG_ 545 RFL_Obj08B_ProbStatBarrier "Probability of the object being a stationary road barrier";
CM_ SG_ 545 RFL_Obj08B_ProbStatObst "Probability of the object being a stationary obstacle";
CM_ SG_ 545 RFL_Obj08B_MovingProbability "Object has been observed moving over the ground";
CM_ SG_ 545 RFL_Obj08B_MovingObserved "Object has been observed moving over the ground since it was first detected";
CM_ SG_ 545 RFL_Obj08B_BehaviorType "Indicates that which behavior the object associated for";
CM_ SG_ 546 RFL_Obj09A_CRC "CRC - Autosar E2E Profile 5";
CM_ SG_ 546 RFL_Obj09A_Ay "Object relative acceleration in Y direction";
CM_ SG_ 546 RFL_Obj09A_HeadingYawAngle "Object heading yaw angle";
CM_ SG_ 546 RFL_Obj09A_Length "Object Length";
CM_ SG_ 546 RFL_Obj09A_Width "Object Width";
CM_ SG_ 546 RFL_Obj09A_Height "Object Height";
CM_ SG_ 546 RFL_Obj09A_DxVnce "Variance of object position in X direction";
CM_ SG_ 546 RFL_Obj09A_DyVnce "Variance of object position in Y direction";
CM_ SG_ 546 RFL_Obj09A_DzVnce "Variance of object position in Z direction";
CM_ SG_ 546 RFL_Obj09A_AliveCtr "Alive counter - Autosar E2E Profile 5";
CM_ SG_ 546 RFL_Obj09A_VxVnce "Variance of object relative velocity in X direction";
CM_ SG_ 546 RFL_Obj09A_VyVnce "Variance of object relative velocity in Y direction";
CM_ SG_ 546 RFL_Obj09A_AxVnce "Variance of object relative acceleration in X direction";
CM_ SG_ 546 RFL_Obj09A_AyVnce "Variance of object relative acceleration in Y direction";
CM_ SG_ 546 RFL_Obj09A_RefPosIndex "Reference Position of the detected objects";
CM_ SG_ 546 RFL_Obj09A_DxDyCoVnce "Covariance of Dx and Dy";
CM_ SG_ 546 RFL_Obj09A_DxVxCoVnce "Covariance of Dx and Vx";
CM_ SG_ 546 RFL_Obj09A_ProtBlockCtr "Protocol-Signal: Block-Counter";
CM_ SG_ 546 RFL_Obj09A_DyVxCoVnce "Covariance of Dy and Ax";
CM_ SG_ 546 RFL_Obj09A_DxVyCoVnce "Covariance of Dx and Vy";
CM_ SG_ 546 RFL_Obj09A_DyVyCoVnce "Covariance of Dy and Vy";
CM_ SG_ 546 RFL_Obj09A_VxVyCoVnce "Covariance of Vx and Vy";
CM_ SG_ 546 RFL_Obj09A_DxAxCoVnce "Covariance of Dx and Ax";
CM_ SG_ 546 RFL_Obj09A_DyAxCoVnce "Covariance of Dy and Ax";
CM_ SG_ 546 RFL_Obj09A_VxAxCoVnce "Covariance of Vx and Ax";
CM_ SG_ 546 RFL_Obj09A_ID "Unique Object ID";
CM_ SG_ 546 RFL_Obj09A_VyAxCoVnce "Covariance of Vy and Ax";
CM_ SG_ 546 RFL_Obj09A_DxAyCoVnce "Covariance of Dx and Ay";
CM_ SG_ 546 RFL_Obj09A_DyAyCoVnce "Covariance of Dy and Ay";
CM_ SG_ 546 RFL_Obj09A_VxAyCoVnce "Covariance of Vx and Ay";
CM_ SG_ 546 RFL_Obj09A_VyAyCoVnce "Covariance of Vy and Ay";
CM_ SG_ 546 RFL_Obj09A_AxAyCoVnce "Covariance of Ax and Ay";
CM_ SG_ 546 RFL_Obj09A_Measured "Object is measured or not";
CM_ SG_ 546 RFL_Obj09A_HeadingYawAngleVnce "Variance of object heading yaw angle";
CM_ SG_ 546 RFL_Obj09A_Dx "Object position in X direction";
CM_ SG_ 546 RFL_Obj09A_LengthVnce "Variance of object Length";
CM_ SG_ 546 RFL_Obj09A_WidthVnce "Variance of object Width";
CM_ SG_ 546 RFL_Obj09A_HeightVnce "Variance of object Height";
CM_ SG_ 546 RFL_Obj09A_ProbExist "Existence probability of object";
CM_ SG_ 546 RFL_Obj09A_ProbObstacle "Probability of the object being an Obstacle";
CM_ SG_ 546 RFL_Obj09A_ProbNonObstacle "Probability of the object being a Non-Obstacle";
CM_ SG_ 546 RFL_Obj09A_ProbMobileObst "Probability of the object being a mobile obstacle";
CM_ SG_ 546 RFL_Obj09A_Dz "Object position in Z direction";
CM_ SG_ 546 RFL_Obj09A_Dy "Object position in Y direction";
CM_ SG_ 546 RFL_Obj09A_Valid "Object is valid or not";
CM_ SG_ 546 RFL_Obj09A_Vx "Object relative velocity in X direction";
CM_ SG_ 546 RFL_Obj09A_Vy "Object relative velocity in Y direction";
CM_ SG_ 546 RFL_Obj09A_Ax "Object relative acceleration in X direction";
CM_ SG_ 547 RFL_Obj09B_CRC "CRC - Autosar E2E Profile 5";
CM_ SG_ 547 RFL_Obj09B_AliveCtr "Alive counter - Autosar E2E Profile 5";
CM_ SG_ 547 RFL_Obj09B_ProtBlockCtr "Protocol-Signal: Block-Counter";
CM_ SG_ 547 RFL_Obj09B_ProbMob4PlusWhl "Probability of a mobile object which has 4 or more wheels";
CM_ SG_ 547 RFL_Obj09B_ProbMob2Whl "Probability of a mobile object being 2-wheels vehicle";
CM_ SG_ 547 RFL_Obj09B_ProbMobPed "Probability of a mobile object being a pedestrian";
CM_ SG_ 547 RFL_Obj09B_Prob4PlusWhlCAR "Probability of a mobile object which has 4 or more wheels--passenger car";
CM_ SG_ 547 RFL_Obj09B_Prob4PlusWhlbHGV "Probability of a mobile object which has 4 or more wheels--commercial vehicle (Truck)";
CM_ SG_ 547 RFL_Obj09B_ProbGNDReflex "Probability of the object being a ground reflex";
CM_ SG_ 547 RFL_Obj09B_ProbStatBarrier "Probability of the object being a stationary road barrier";
CM_ SG_ 547 RFL_Obj09B_ProbStatObst "Probability of the object being a stationary obstacle";
CM_ SG_ 547 RFL_Obj09B_MovingProbability "Object has been observed moving over the ground";
CM_ SG_ 547 RFL_Obj09B_MovingObserved "Object has been observed moving over the ground since it was first detected";
CM_ SG_ 547 RFL_Obj09B_BehaviorType "Indicates that which behavior the object associated for";
BA_DEF_ BO_  "GenMsgSendType" ENUM  "cyclic","NoMsgSendType","IfActive","Event","CA","CE";
BA_DEF_ BO_  "GenMsgCycleTime" INT 0 0;
BA_DEF_ SG_  "GenSigSendType" ENUM  "cyclic","OnChange","OnWrite","IfActive","OnChangeWithRepetition","OnWriteWithRepetition","IfActiveWithRepetition","CA","CE","Event";
BA_DEF_ SG_  "GenSigStartValue" INT 0 0;
BA_DEF_  "DBName" STRING ;
BA_DEF_ BO_  "CANFD_BRS" ENUM  "0","1";
BA_DEF_ BO_  "VFrameFormat" ENUM  "StandardCAN","ExtendedCAN","reserved","reserved","reserved","reserved","reserved","reserved","reserved","reserved","reserved","reserved","reserved","reserved","StandardCAN_FD","ExtendedCAN_FD";
BA_DEF_  "BusBaudateData" INT 0 10000;
BA_DEF_  "BusBaudateOther" INT 0 10000;
BA_DEF_ BO_  "GenMsgILSupport" ENUM  "No","Yes";
BA_DEF_  "BusType" STRING ;
BA_DEF_DEF_  "GenMsgSendType" "cyclic";
BA_DEF_DEF_  "GenMsgCycleTime" 0;
BA_DEF_DEF_  "GenSigSendType" "cyclic";
BA_DEF_DEF_  "GenSigStartValue" 0;
BA_DEF_DEF_  "DBName" "";
BA_DEF_DEF_  "CANFD_BRS" "1";
BA_DEF_DEF_  "VFrameFormat" "";
BA_DEF_DEF_  "BusBaudateData" 2;
BA_DEF_DEF_  "BusBaudateOther" 500;
BA_DEF_DEF_  "GenMsgILSupport" "Yes";
BA_DEF_DEF_  "BusType" "CAN FD";
BA_ "DBName" "BJEV_5R1V1D_FrontCorner_BL09";
BA_ "GenMsgCycleTime" BO_ 63 20;
BA_ "VFrameFormat" BO_ 63 14;
BA_ "GenMsgCycleTime" BO_ 76 50;
BA_ "VFrameFormat" BO_ 76 14;
BA_ "GenMsgCycleTime" BO_ 82 50;
BA_ "VFrameFormat" BO_ 82 14;
BA_ "GenMsgCycleTime" BO_ 86 50;
BA_ "VFrameFormat" BO_ 86 14;
BA_ "GenMsgSendType" BO_ 517 3;
BA_ "VFrameFormat" BO_ 517 14;
BA_ "GenMsgSendType" BO_ 528 3;
BA_ "VFrameFormat" BO_ 528 14;
BA_ "GenMsgSendType" BO_ 529 3;
BA_ "VFrameFormat" BO_ 529 14;
BA_ "GenMsgSendType" BO_ 530 3;
BA_ "VFrameFormat" BO_ 530 14;
BA_ "GenMsgSendType" BO_ 531 3;
BA_ "VFrameFormat" BO_ 531 14;
BA_ "GenMsgSendType" BO_ 532 3;
BA_ "VFrameFormat" BO_ 532 14;
BA_ "GenMsgSendType" BO_ 533 3;
BA_ "VFrameFormat" BO_ 533 14;
BA_ "GenMsgSendType" BO_ 534 3;
BA_ "VFrameFormat" BO_ 534 14;
BA_ "GenMsgSendType" BO_ 535 3;
BA_ "VFrameFormat" BO_ 535 14;
BA_ "GenMsgSendType" BO_ 536 3;
BA_ "VFrameFormat" BO_ 536 14;
BA_ "GenMsgSendType" BO_ 537 3;
BA_ "VFrameFormat" BO_ 537 14;
BA_ "GenMsgSendType" BO_ 538 3;
BA_ "VFrameFormat" BO_ 538 14;
BA_ "GenMsgSendType" BO_ 539 3;
BA_ "VFrameFormat" BO_ 539 14;
BA_ "GenMsgSendType" BO_ 540 3;
BA_ "VFrameFormat" BO_ 540 14;
BA_ "GenMsgSendType" BO_ 541 3;
BA_ "VFrameFormat" BO_ 541 14;
BA_ "GenMsgSendType" BO_ 542 3;
BA_ "VFrameFormat" BO_ 542 14;
BA_ "GenMsgSendType" BO_ 543 3;
BA_ "VFrameFormat" BO_ 543 14;
BA_ "GenMsgSendType" BO_ 544 3;
BA_ "VFrameFormat" BO_ 544 14;
BA_ "GenMsgSendType" BO_ 545 3;
BA_ "VFrameFormat" BO_ 545 14;
BA_ "GenMsgSendType" BO_ 546 3;
BA_ "VFrameFormat" BO_ 546 14;
BA_ "GenMsgSendType" BO_ 547 3;
BA_ "VFrameFormat" BO_ 547 14;
BA_ "GenSigStartValue" SG_ 63 CMRR_FL_Decel_FCTB 32773;
BA_ "GenSigStartValue" SG_ 517 RFL_ObjHdr_MountPosY 128;
BA_ "GenSigStartValue" SG_ 517 RFL_ObjHdr_MountPosX 256;
BA_ "GenSigStartValue" SG_ 517 RFL_ObjHdr_YawMountAngle 32768;
BA_ "GenSigStartValue" SG_ 517 RFL_ObjHdr_YawAngleLower 16384;
BA_ "GenSigStartValue" SG_ 517 RFL_ObjHdr_YawAngleUpper 16384;
BA_ "GenSigStartValue" SG_ 517 RFL_ObjHdr_PitchMountAngle 2048;
BA_ "GenSigStartValue" SG_ 517 RFL_ObjHdr_PitchAngleLower 2048;
BA_ "GenSigStartValue" SG_ 517 RFL_ObjHdr_PitchAngleUpper 2048;
BA_ "GenSigStartValue" SG_ 517 RFL_ObjHdr_RollMountAngle 2048;
BA_ "GenSigStartValue" SG_ 517 RFL_ObjHdr_ProtocolVersion 261;
BA_ "GenSigStartValue" SG_ 528 RFL_Obj00A_Ay 256;
BA_ "GenSigStartValue" SG_ 528 RFL_Obj00A_HeadingYawAngle 256;
BA_ "GenSigStartValue" SG_ 528 RFL_Obj00A_Dx 4096;
BA_ "GenSigStartValue" SG_ 528 RFL_Obj00A_Dz 20;
BA_ "GenSigStartValue" SG_ 528 RFL_Obj00A_Dy 1024;
BA_ "GenSigStartValue" SG_ 528 RFL_Obj00A_Vx 2048;
BA_ "GenSigStartValue" SG_ 528 RFL_Obj00A_Vy 512;
BA_ "GenSigStartValue" SG_ 528 RFL_Obj00A_Ax 512;
BA_ "GenSigStartValue" SG_ 530 RFL_Obj01A_Ay 256;
BA_ "GenSigStartValue" SG_ 530 RFL_Obj01A_HeadingYawAngle 256;
BA_ "GenSigStartValue" SG_ 530 RFL_Obj01A_Dx 4096;
BA_ "GenSigStartValue" SG_ 530 RFL_Obj01A_Dz 20;
BA_ "GenSigStartValue" SG_ 530 RFL_Obj01A_Dy 1024;
BA_ "GenSigStartValue" SG_ 530 RFL_Obj01A_Vx 2048;
BA_ "GenSigStartValue" SG_ 530 RFL_Obj01A_Vy 512;
BA_ "GenSigStartValue" SG_ 530 RFL_Obj01A_Ax 512;
BA_ "GenSigStartValue" SG_ 532 RFL_Obj02A_Ay 256;
BA_ "GenSigStartValue" SG_ 532 RFL_Obj02A_HeadingYawAngle 256;
BA_ "GenSigStartValue" SG_ 532 RFL_Obj02A_Dx 4096;
BA_ "GenSigStartValue" SG_ 532 RFL_Obj02A_Dz 20;
BA_ "GenSigStartValue" SG_ 532 RFL_Obj02A_Dy 1024;
BA_ "GenSigStartValue" SG_ 532 RFL_Obj02A_Vx 2048;
BA_ "GenSigStartValue" SG_ 532 RFL_Obj02A_Vy 512;
BA_ "GenSigStartValue" SG_ 532 RFL_Obj02A_Ax 512;
BA_ "GenSigStartValue" SG_ 534 RFL_Obj03A_Ay 256;
BA_ "GenSigStartValue" SG_ 534 RFL_Obj03A_HeadingYawAngle 256;
BA_ "GenSigStartValue" SG_ 534 RFL_Obj03A_Dx 4096;
BA_ "GenSigStartValue" SG_ 534 RFL_Obj03A_Dz 20;
BA_ "GenSigStartValue" SG_ 534 RFL_Obj03A_Dy 1024;
BA_ "GenSigStartValue" SG_ 534 RFL_Obj03A_Vx 2048;
BA_ "GenSigStartValue" SG_ 534 RFL_Obj03A_Vy 512;
BA_ "GenSigStartValue" SG_ 534 RFL_Obj03A_Ax 512;
BA_ "GenSigStartValue" SG_ 536 RFL_Obj04A_Ay 256;
BA_ "GenSigStartValue" SG_ 536 RFL_Obj04A_HeadingYawAngle 256;
BA_ "GenSigStartValue" SG_ 536 RFL_Obj04A_Dx 4096;
BA_ "GenSigStartValue" SG_ 536 RFL_Obj04A_Dz 20;
BA_ "GenSigStartValue" SG_ 536 RFL_Obj04A_Dy 1024;
BA_ "GenSigStartValue" SG_ 536 RFL_Obj04A_Vx 2048;
BA_ "GenSigStartValue" SG_ 536 RFL_Obj04A_Vy 512;
BA_ "GenSigStartValue" SG_ 536 RFL_Obj04A_Ax 512;
BA_ "GenSigStartValue" SG_ 538 RFL_Obj05A_Ay 256;
BA_ "GenSigStartValue" SG_ 538 RFL_Obj05A_HeadingYawAngle 256;
BA_ "GenSigStartValue" SG_ 538 RFL_Obj05A_Dx 4096;
BA_ "GenSigStartValue" SG_ 538 RFL_Obj05A_Dz 20;
BA_ "GenSigStartValue" SG_ 538 RFL_Obj05A_Dy 1024;
BA_ "GenSigStartValue" SG_ 538 RFL_Obj05A_Vx 2048;
BA_ "GenSigStartValue" SG_ 538 RFL_Obj05A_Vy 512;
BA_ "GenSigStartValue" SG_ 538 RFL_Obj05A_Ax 512;
BA_ "GenSigStartValue" SG_ 540 RFL_Obj06A_Ay 256;
BA_ "GenSigStartValue" SG_ 540 RFL_Obj06A_HeadingYawAngle 256;
BA_ "GenSigStartValue" SG_ 540 RFL_Obj06A_Dx 4096;
BA_ "GenSigStartValue" SG_ 540 RFL_Obj06A_Dz 20;
BA_ "GenSigStartValue" SG_ 540 RFL_Obj06A_Dy 1024;
BA_ "GenSigStartValue" SG_ 540 RFL_Obj06A_Vx 2048;
BA_ "GenSigStartValue" SG_ 540 RFL_Obj06A_Vy 512;
BA_ "GenSigStartValue" SG_ 540 RFL_Obj06A_Ax 512;
BA_ "GenSigStartValue" SG_ 542 RFL_Obj07A_Ay 256;
BA_ "GenSigStartValue" SG_ 542 RFL_Obj07A_HeadingYawAngle 256;
BA_ "GenSigStartValue" SG_ 542 RFL_Obj07A_Dx 4096;
BA_ "GenSigStartValue" SG_ 542 RFL_Obj07A_Dz 20;
BA_ "GenSigStartValue" SG_ 542 RFL_Obj07A_Dy 1024;
BA_ "GenSigStartValue" SG_ 542 RFL_Obj07A_Vx 2048;
BA_ "GenSigStartValue" SG_ 542 RFL_Obj07A_Vy 512;
BA_ "GenSigStartValue" SG_ 542 RFL_Obj07A_Ax 512;
BA_ "GenSigStartValue" SG_ 544 RFL_Obj08A_Ay 256;
BA_ "GenSigStartValue" SG_ 544 RFL_Obj08A_HeadingYawAngle 256;
BA_ "GenSigStartValue" SG_ 544 RFL_Obj08A_Dx 4096;
BA_ "GenSigStartValue" SG_ 544 RFL_Obj08A_Dz 20;
BA_ "GenSigStartValue" SG_ 544 RFL_Obj08A_Dy 1024;
BA_ "GenSigStartValue" SG_ 544 RFL_Obj08A_Vx 2048;
BA_ "GenSigStartValue" SG_ 544 RFL_Obj08A_Vy 512;
BA_ "GenSigStartValue" SG_ 544 RFL_Obj08A_Ax 512;
BA_ "GenSigStartValue" SG_ 546 RFL_Obj09A_Ay 256;
BA_ "GenSigStartValue" SG_ 546 RFL_Obj09A_HeadingYawAngle 256;
BA_ "GenSigStartValue" SG_ 546 RFL_Obj09A_Dx 4096;
BA_ "GenSigStartValue" SG_ 546 RFL_Obj09A_Dz 20;
BA_ "GenSigStartValue" SG_ 546 RFL_Obj09A_Dy 1024;
BA_ "GenSigStartValue" SG_ 546 RFL_Obj09A_Vx 2048;
BA_ "GenSigStartValue" SG_ 546 RFL_Obj09A_Vy 512;
BA_ "GenSigStartValue" SG_ 546 RFL_Obj09A_Ax 512;
VAL_ 3221225472 ADAS_ModulationOffRequest 0 "No request" 1 "Modulation off" 2 "Reserved" 3 "Reserved" ;
VAL_ 63 CMRR_FL_DecelReq 0 "Not Active" 1 "Active" ;
VAL_ 63 CMRR_FL_Lvl_HBA 0 "Level 0" 1 "Level 1" 2 "Level 2" 3 "Level 3" 4 "Reserved" 5 "Reserved" 6 "Reserved" 7 "Reserved" ;
VAL_ 63 CMRR_FL_Req_HBA 0 "Not Active" 1 "Active" ;
VAL_ 63 CMRR_FL_Req_Prefill 0 "Not Active" 1 "Active" ;
VAL_ 76 RFR_FCTASwtFb 0 "Default" 1 "Switch Off" 2 "Switch On" 3 "Fault" ;
VAL_ 76 RFR_FCTBSwtFb 0 "Default" 1 "Switch Off" 2 "Switch On" 3 "Fault" ;
VAL_ 82 RFL_Modulation_Status 0 "Normal" 1 "Time Sync Fail and Modulation Fail" 2 "Time Sync Correct and Modulation Fail" 3 "Reserved" ;
VAL_ 82 RFL_Status_SensorState 0 "SENSOR FULLY OPERATIONAL" 1 "HW MALFUNCTION" 2 "DSP ISSUES" 3 "COMMUNICATION ERRORS" 4 "MISALIGNMENT (OUT OF SPEC)" 5 "SENSOR BLIDNESS DETECTED" 6 "SENSOR DISTUBED" 7 "OTHER ISSUES" 8 "DSP off by request" 9 "RESERVED2" 10 "RESERVED3" 11 "RESERVED4" 12 "RESERVED5" 13 "RESERVED6" 14 "RESERVED7" 15 "INVALID" ;
VAL_ 86 RFR_Modulation_Status 0 "Normal" 1 "Time Sync Fail and Modulation Fail" 2 "Time Sync Correct and Modulation Fail" 3 "Reserved" ;
VAL_ 86 RFR_Status_SensorState 0 "SENSOR FULLY OPERATIONAL" 1 "HW MALFUNCTION" 2 "DSP ISSUES" 3 "COMMUNICATION ERRORS" 4 "MISALIGNMENT (OUT OF SPEC)" 5 "SENSOR BLIDNESS DETECTED" 6 "SENSOR DISTUBED" 7 "OTHER ISSUES" 8 "DSP off by request" 9 "RESERVED2" 10 "RESERVED3" 11 "RESERVED4" 12 "RESERVED5" 13 "RESERVED6" 14 "RESERVED7" 15 "INVALID" ;
VAL_ 517 RFL_ObjHdr_ObjectDownSel 0 "no downselection" 1 "downselected" ;
VAL_ 517 RFL_ObjHdr_AziOutOfSpec 0 "In spec Azimuth Alignemdn" 1 "Out of spec Azimuth Alignement" ;
VAL_ 517 RFL_ObjHdr_ElevOutOfSpec 0 "In Spec Elevation Alignment" 1 "Out of spec Elevation Alignement" ;
VAL_ 517 RFL_ObjHdr_SensorState 0 "SENSOR FULLY OPERATIONAL" 1 "HW MALFUNCTION" 2 "DSP ISSUES" 3 "COMMUNICATION ERRORS" 4 "MISALIGNMENT (OUT OF SPEC)" 5 "SENSOR BLIDNESS DETECTED" 6 "SENSOR DISTUBED" 7 "OTHER ISSUES" 8 "RESERVED1" 9 "RESERVED2" 10 "RESERVED3" 11 "RESERVED4" 12 "RESERVED5" 13 "RESERVED6" 14 "RESERVED7" 15 "INVALID" ;
VAL_ 528 RFL_Obj00A_RefPosIndex 0 "Front corner left" 1 "Front center" 2 "Front corner right" 3 "Front wheelcase left" 4 "Front wheelcase right" 5 "Side middle left" 6 "Side middle right" 7 "Rear wheelcase left" 8 "Rear wheelcase right" 9 "Rear corner left" 10 "Rear center" 11 "Rear corner right" 12 "Object center" 13 "Rear wheelcase center" 14 "Front wheelcase center" 15 "Invalid" ;
VAL_ 528 RFL_Obj00A_Measured 0 "not measured" 1 "measured" ;
VAL_ 528 RFL_Obj00A_Valid 0 "not valid" 1 "valid" ;
VAL_ 529 RFL_Obj00B_BehaviorType 0 "No_Target" 1 "FCTA" 2 "RCTA" 3 "BSD" 4 "LCA" 5 "HWA" 6 "Reserved1" 7 "Reserved2" ;
VAL_ 530 RFL_Obj01A_RefPosIndex 0 "Front corner left" 1 "Front center" 2 "Front corner right" 3 "Front wheelcase left" 4 "Front wheelcase right" 5 "Side middle left" 6 "Side middle right" 7 "Rear wheelcase left" 8 "Rear wheelcase right" 9 "Rear corner left" 10 "Rear center" 11 "Rear corner right" 12 "Object center" 13 "Rear wheelcase center" 14 "Front wheelcase center" 15 "Invalid" ;
VAL_ 530 RFL_Obj01A_Measured 0 "not measured" 1 "measured" ;
VAL_ 530 RFL_Obj01A_Valid 0 "not valid" 1 "valid" ;
VAL_ 531 RFL_Obj01B_BehaviorType 0 "No_Target" 1 "FCTA" 2 "RCTA" 3 "BSD" 4 "LCA" 5 "HWA" 6 "Reserved1" 7 "Reserved2" ;
VAL_ 532 RFL_Obj02A_RefPosIndex 0 "Front corner left" 1 "Front center" 2 "Front corner right" 3 "Front wheelcase left" 4 "Front wheelcase right" 5 "Side middle left" 6 "Side middle right" 7 "Rear wheelcase left" 8 "Rear wheelcase right" 9 "Rear corner left" 10 "Rear center" 11 "Rear corner right" 12 "Object center" 13 "Rear wheelcase center" 14 "Front wheelcase center" 15 "Invalid" ;
VAL_ 532 RFL_Obj02A_Measured 0 "not measured" 1 "measured" ;
VAL_ 532 RFL_Obj02A_Valid 0 "not valid" 1 "valid" ;
VAL_ 533 RFL_Obj02B_BehaviorType 0 "No_Target" 1 "FCTA" 2 "RCTA" 3 "BSD" 4 "LCA" 5 "HWA" 6 "Reserved1" 7 "Reserved2" ;
VAL_ 534 RFL_Obj03A_RefPosIndex 0 "Front corner left" 1 "Front center" 2 "Front corner right" 3 "Front wheelcase left" 4 "Front wheelcase right" 5 "Side middle left" 6 "Side middle right" 7 "Rear wheelcase left" 8 "Rear wheelcase right" 9 "Rear corner left" 10 "Rear center" 11 "Rear corner right" 12 "Object center" 13 "Rear wheelcase center" 14 "Front wheelcase center" 15 "Invalid" ;
VAL_ 534 RFL_Obj03A_Measured 0 "not measured" 1 "measured" ;
VAL_ 534 RFL_Obj03A_Valid 0 "not valid" 1 "valid" ;
VAL_ 535 RFL_Obj03B_BehaviorType 0 "No_Target" 1 "FCTA" 2 "RCTA" 3 "BSD" 4 "LCA" 5 "HWA" 6 "Reserved1" 7 "Reserved2" ;
VAL_ 536 RFL_Obj04A_RefPosIndex 0 "Front corner left" 1 "Front center" 2 "Front corner right" 3 "Front wheelcase left" 4 "Front wheelcase right" 5 "Side middle left" 6 "Side middle right" 7 "Rear wheelcase left" 8 "Rear wheelcase right" 9 "Rear corner left" 10 "Rear center" 11 "Rear corner right" 12 "Object center" 13 "Rear wheelcase center" 14 "Front wheelcase center" 15 "Invalid" ;
VAL_ 536 RFL_Obj04A_Measured 0 "not measured" 1 "measured" ;
VAL_ 536 RFL_Obj04A_Valid 0 "not valid" 1 "valid" ;
VAL_ 537 RFL_Obj04B_BehaviorType 0 "No_Target" 1 "FCTA" 2 "RCTA" 3 "BSD" 4 "LCA" 5 "HWA" 6 "Reserved1" 7 "Reserved2" ;
VAL_ 538 RFL_Obj05A_RefPosIndex 0 "Front corner left" 1 "Front center" 2 "Front corner right" 3 "Front wheelcase left" 4 "Front wheelcase right" 5 "Side middle left" 6 "Side middle right" 7 "Rear wheelcase left" 8 "Rear wheelcase right" 9 "Rear corner left" 10 "Rear center" 11 "Rear corner right" 12 "Object center" 13 "Rear wheelcase center" 14 "Front wheelcase center" 15 "Invalid" ;
VAL_ 538 RFL_Obj05A_Measured 0 "not measured" 1 "measured" ;
VAL_ 538 RFL_Obj05A_Valid 0 "not valid" 1 "valid" ;
VAL_ 539 RFL_Obj05B_BehaviorType 0 "No_Target" 1 "FCTA" 2 "RCTA" 3 "BSD" 4 "LCA" 5 "HWA" 6 "Reserved1" 7 "Reserved2" ;
VAL_ 540 RFL_Obj06A_RefPosIndex 0 "Front corner left" 1 "Front center" 2 "Front corner right" 3 "Front wheelcase left" 4 "Front wheelcase right" 5 "Side middle left" 6 "Side middle right" 7 "Rear wheelcase left" 8 "Rear wheelcase right" 9 "Rear corner left" 10 "Rear center" 11 "Rear corner right" 12 "Object center" 13 "Rear wheelcase center" 14 "Front wheelcase center" 15 "Invalid" ;
VAL_ 540 RFL_Obj06A_Measured 0 "not measured" 1 "measured" ;
VAL_ 540 RFL_Obj06A_Valid 0 "not valid" 1 "valid" ;
VAL_ 541 RFL_Obj06B_BehaviorType 0 "No_Target" 1 "FCTA" 2 "RCTA" 3 "BSD" 4 "LCA" 5 "HWA" 6 "Reserved1" 7 "Reserved2" ;
VAL_ 542 RFL_Obj07A_RefPosIndex 0 "Front corner left" 1 "Front center" 2 "Front corner right" 3 "Front wheelcase left" 4 "Front wheelcase right" 5 "Side middle left" 6 "Side middle right" 7 "Rear wheelcase left" 8 "Rear wheelcase right" 9 "Rear corner left" 10 "Rear center" 11 "Rear corner right" 12 "Object center" 13 "Rear wheelcase center" 14 "Front wheelcase center" 15 "Invalid" ;
VAL_ 542 RFL_Obj07A_Measured 0 "not measured" 1 "measured" ;
VAL_ 542 RFL_Obj07A_Valid 0 "not valid" 1 "valid" ;
VAL_ 543 RFL_Obj07B_BehaviorType 0 "No_Target" 1 "FCTA" 2 "RCTA" 3 "BSD" 4 "LCA" 5 "HWA" 6 "Reserved1" 7 "Reserved2" ;
VAL_ 544 RFL_Obj08A_RefPosIndex 0 "Front corner left" 1 "Front center" 2 "Front corner right" 3 "Front wheelcase left" 4 "Front wheelcase right" 5 "Side middle left" 6 "Side middle right" 7 "Rear wheelcase left" 8 "Rear wheelcase right" 9 "Rear corner left" 10 "Rear center" 11 "Rear corner right" 12 "Object center" 13 "Rear wheelcase center" 14 "Front wheelcase center" 15 "Invalid" ;
VAL_ 544 RFL_Obj08A_Measured 0 "not measured" 1 "measured" ;
VAL_ 544 RFL_Obj08A_Valid 0 "not valid" 1 "valid" ;
VAL_ 545 RFL_Obj08B_BehaviorType 0 "No_Target" 1 "FCTA" 2 "RCTA" 3 "BSD" 4 "LCA" 5 "HWA" 6 "Reserved1" 7 "Reserved2" ;
VAL_ 546 RFL_Obj09A_RefPosIndex 0 "Front corner left" 1 "Front center" 2 "Front corner right" 3 "Front wheelcase left" 4 "Front wheelcase right" 5 "Side middle left" 6 "Side middle right" 7 "Rear wheelcase left" 8 "Rear wheelcase right" 9 "Rear corner left" 10 "Rear center" 11 "Rear corner right" 12 "Object center" 13 "Rear wheelcase center" 14 "Front wheelcase center" 15 "Invalid" ;
VAL_ 546 RFL_Obj09A_Measured 0 "not measured" 1 "measured" ;
VAL_ 546 RFL_Obj09A_Valid 0 "not valid" 1 "valid" ;
VAL_ 547 RFL_Obj09B_BehaviorType 0 "No_Target" 1 "FCTA" 2 "RCTA" 3 "BSD" 4 "LCA" 5 "HWA" 6 "Reserved1" 7 "Reserved2" ;
